VERSION ""

NS_ :

BS_:

BU_: MM5 STMM DD PDM BMS PM VCU

BO_ 3221225472 VECTOR__INDEPENDENT_SIG_MSG: 0 Vector__XXX
 SG_ VCU_counterMsg172 : 0|4@1+ (1,0) [0|15] "" Vector__XXX
 SG_ VCU_groundSpeed : 0|16@1- (0.1,0) [0|120] "mph" Vector__XXX
 SG_ VCU_groundSpeedLeft : 0|16@1- (0.1,0) [0|120] "mph" Vector__XXX
 SG_ VCU_groundSpeedRight : 0|16@1- (0.1,0) [0|120] "mph" Vector__XXX
 SG_ VCU_driveSpeed : 0|16@1- (0.1,0) [0|120] "mph" Vector__XXX
 SG_ VCU_driveSpeedLeft : 0|16@1- (0.1,0) [0|120] "mph" Vector__XXX
 SG_ VCU_driveSpeedRight : 0|16@1- (0.1,0) [0|120] "mph" Vector__XXX

BO_ 173 VCU_173: 8 Vector__XXX
 SG_ VCU_driveSpeed : 32|16@1- (0.1,0) [-3276.8|3276.7] "mph" Vector__XXX
 SG_ VCU_groundSpeed : 16|16@1- (0.1,0) [-3276.8|3276.7] "mph" Vector__XXX
 SG_ VCU_counterMsg173 : 0|4@1+ (1,0) [0|15] "" Vector__XXX

BO_ 172 VCU_172: 8 Vector__XXX
 SG_ VCU_brakePosR : 24|16@1- (0.1,0) [-3276.8|3276.7] "%" Vector__XXX
 SG_ VCU_brakePosF : 8|16@1- (0.1,0) [-3276.8|3276.7] "%" Vector__XXX
 SG_ VCU_counterMsg172 : 0|4@1+ (1,0) [0|15] "" Vector__XXX

BO_ 171 VCU_171: 8 Vector__XXX
 SG_ VCU_throttlePos2 : 32|16@1- (0.1,0) [0|0] "%" Vector__XXX
 SG_ VCU_throttlePos1 : 16|16@1- (0.1,0) [-3276.8|3276.7] "%" Vector__XXX
 SG_ VCU_counterMsg171 : 0|4@1+ (1,0) [0|15] "" Vector__XXX

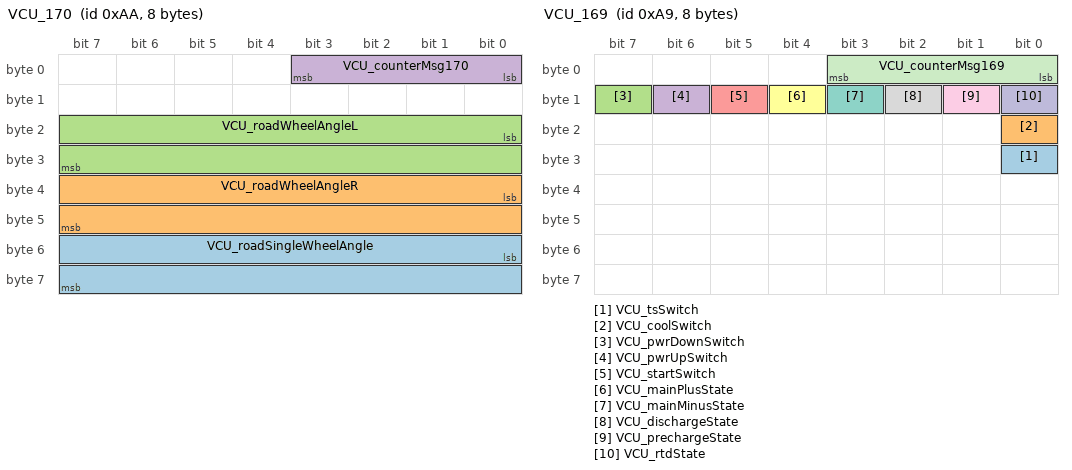
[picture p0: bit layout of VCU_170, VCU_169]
BO_ 170 VCU_170: 8 Vector__XXX
 SG_ VCU_roadSingleWheelAngle : 48|16@1- (0.1,0) [-3276.8|3276.7] "deg" Vector__XXX
 SG_ VCU_roadWheelAngleR : 32|16@1- (0.1,0) [-3276.8|3276.7] "deg" Vector__XXX
 SG_ VCU_roadWheelAngleL : 16|16@1- (0.1,0) [-3276.8|3276.7] "deg" Vector__XXX
 SG_ VCU_counterMsg170 : 0|4@1+ (1,0) [0|15] "" Vector__XXX

BO_ 169 VCU_169: 8 Vector__XXX
 SG_ VCU_tsSwitch : 24|1@1+ (1,0) [0|1] "" Vector__XXX
 SG_ VCU_coolSwitch : 16|1@1+ (1,0) [0|1] "" Vector__XXX
 SG_ VCU_pwrDownSwitch : 15|1@1+ (1,0) [0|1] "" Vector__XXX
 SG_ VCU_pwrUpSwitch : 14|1@1+ (1,0) [0|1] "" Vector__XXX
 SG_ VCU_startSwitch : 13|1@1+ (1,0) [0|1] "" Vector__XXX
 SG_ VCU_mainPlusState : 12|1@1+ (1,0) [0|1] "" Vector__XXX
 SG_ VCU_mainMinusState : 11|1@1+ (1,0) [0|1] "" Vector__XXX
 SG_ VCU_dischargeState : 10|1@1+ (1,0) [0|1] "" Vector__XXX
 SG_ VCU_prechargeState : 9|1@1+ (1,0) [0|1] "" Vector__XXX
 SG_ VCU_rtdState : 8|1@1+ (1,0) [0|1] "" Vector__XXX
 SG_ VCU_counterMsg169 : 0|4@1+ (1,0) [0|15] "" Vector__XXX

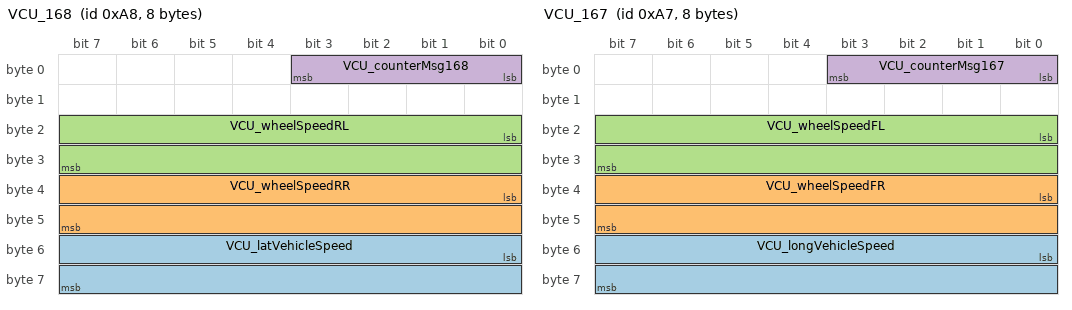
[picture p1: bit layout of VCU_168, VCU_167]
BO_ 168 VCU_168: 8 Vector__XXX
 SG_ VCU_latVehicleSpeed : 48|16@1- (0.1,0) [-3276.8|3276.7] "mph" Vector__XXX
 SG_ VCU_wheelSpeedRR : 32|16@1- (0.1,0) [-3276.8|3276.7] "mph" Vector__XXX
 SG_ VCU_wheelSpeedRL : 16|16@1- (0.1,0) [-3276.8|3276.7] "mph" Vector__XXX
 SG_ VCU_counterMsg168 : 0|4@1+ (1,0) [0|15] "" Vector__XXX

BO_ 167 VCU_167: 8 Vector__XXX
 SG_ VCU_longVehicleSpeed : 48|16@1- (0.1,0) [-3276.8|3276.7] "mph" Vector__XXX
 SG_ VCU_wheelSpeedFR : 32|16@1- (0.1,0) [-3276.8|3276.7] "mph" Vector__XXX
 SG_ VCU_wheelSpeedFL : 16|16@1- (0.1,0) [-3276.8|3276.7] "mph" Vector__XXX
 SG_ VCU_counterMsg167 : 0|4@1+ (1,0) [0|15] "" Vector__XXX

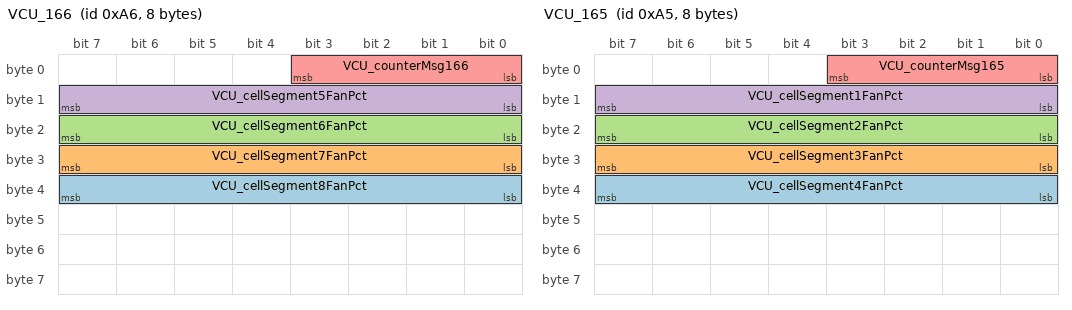
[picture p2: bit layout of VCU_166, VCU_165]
BO_ 166 VCU_166: 8 Vector__XXX
 SG_ VCU_cellSegment8FanPct : 32|8@1+ (1,0) [0|255] "%" Vector__XXX
 SG_ VCU_cellSegment7FanPct : 24|8@1+ (1,0) [0|255] "%" Vector__XXX
 SG_ VCU_cellSegment6FanPct : 16|8@1+ (1,0) [0|255] "%" Vector__XXX
 SG_ VCU_cellSegment5FanPct : 8|8@1+ (1,0) [0|255] "%" Vector__XXX
 SG_ VCU_counterMsg166 : 0|4@1+ (1,0) [0|15] "" Vector__XXX

BO_ 165 VCU_165: 8 Vector__XXX
 SG_ VCU_cellSegment4FanPct : 32|8@1+ (1,0) [0|255] "%" Vector__XXX
 SG_ VCU_cellSegment3FanPct : 24|8@1+ (1,0) [0|255] "%" Vector__XXX
 SG_ VCU_cellSegment2FanPct : 16|8@1+ (1,0) [0|255] "%" Vector__XXX
 SG_ VCU_cellSegment1FanPct : 8|8@1+ (1,0) [0|255] "%" Vector__XXX
 SG_ VCU_counterMsg165 : 0|4@1+ (1,0) [0|15] "" Vector__XXX

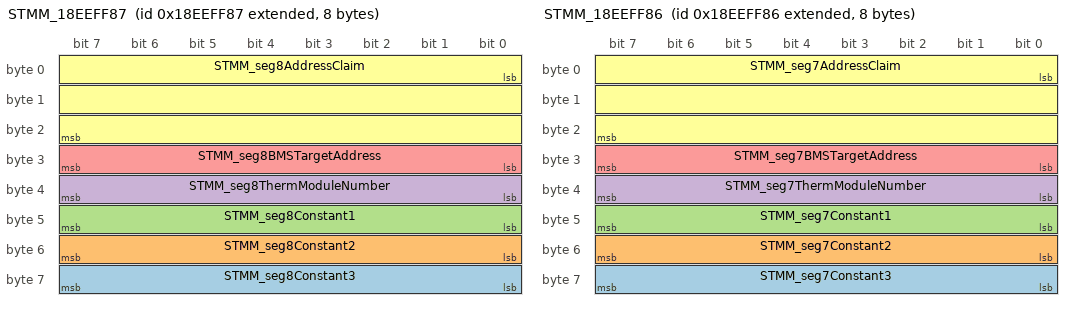
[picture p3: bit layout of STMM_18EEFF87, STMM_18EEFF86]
BO_ 2565799815 STMM_18EEFF87: 8 STMM
 SG_ STMM_seg8Constant3 : 56|8@1+ (1,0) [0|255] "" Vector__XXX
 SG_ STMM_seg8Constant2 : 48|8@1+ (1,0) [0|255] "" Vector__XXX
 SG_ STMM_seg8Constant1 : 40|8@1+ (1,0) [0|255] "" Vector__XXX
 SG_ STMM_seg8ThermModuleNumber : 32|8@1+ (1,0) [0|255] "" Vector__XXX
 SG_ STMM_seg8BMSTargetAddress : 24|8@1+ (1,0) [0|255] "" Vector__XXX
 SG_ STMM_seg8AddressClaim : 0|24@1+ (1,0) [0|16777215] "" Vector__XXX

BO_ 2565799814 STMM_18EEFF86: 8 STMM
 SG_ STMM_seg7Constant3 : 56|8@1+ (1,0) [0|255] "" Vector__XXX
 SG_ STMM_seg7Constant2 : 48|8@1+ (1,0) [0|255] "" Vector__XXX
 SG_ STMM_seg7Constant1 : 40|8@1+ (1,0) [0|255] "" Vector__XXX
 SG_ STMM_seg7ThermModuleNumber : 32|8@1+ (1,0) [0|255] "" Vector__XXX
 SG_ STMM_seg7BMSTargetAddress : 24|8@1+ (1,0) [0|255] "" Vector__XXX
 SG_ STMM_seg7AddressClaim : 0|24@1+ (1,0) [0|16777215] "" Vector__XXX

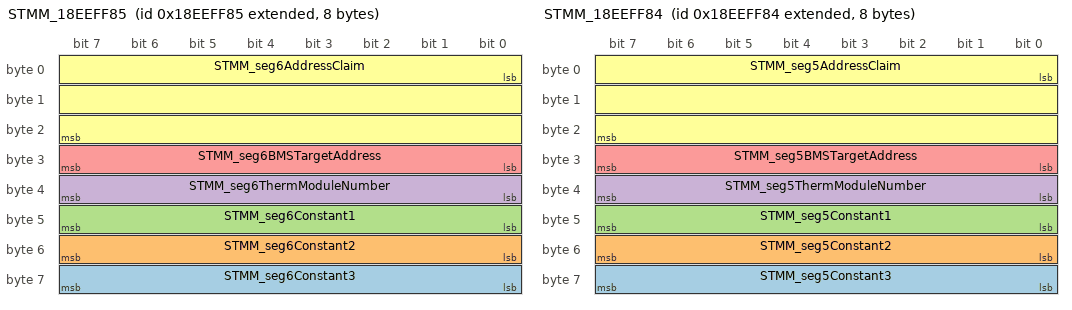
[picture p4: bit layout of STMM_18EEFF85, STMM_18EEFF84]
BO_ 2565799813 STMM_18EEFF85: 8 STMM
 SG_ STMM_seg6Constant3 : 56|8@1+ (1,0) [0|255] "" Vector__XXX
 SG_ STMM_seg6Constant2 : 48|8@1+ (1,0) [0|255] "" Vector__XXX
 SG_ STMM_seg6Constant1 : 40|8@1+ (1,0) [0|255] "" Vector__XXX
 SG_ STMM_seg6ThermModuleNumber : 32|8@1+ (1,0) [0|255] "" Vector__XXX
 SG_ STMM_seg6BMSTargetAddress : 24|8@1+ (1,0) [0|255] "" Vector__XXX
 SG_ STMM_seg6AddressClaim : 0|24@1+ (1,0) [0|16777215] "" Vector__XXX

BO_ 2565799812 STMM_18EEFF84: 8 STMM
 SG_ STMM_seg5Constant3 : 56|8@1+ (1,0) [0|255] "" Vector__XXX
 SG_ STMM_seg5Constant2 : 48|8@1+ (1,0) [0|255] "" Vector__XXX
 SG_ STMM_seg5Constant1 : 40|8@1+ (1,0) [0|255] "" Vector__XXX
 SG_ STMM_seg5ThermModuleNumber : 32|8@1+ (1,0) [0|255] "" Vector__XXX
 SG_ STMM_seg5BMSTargetAddress : 24|8@1+ (1,0) [0|255] "" Vector__XXX
 SG_ STMM_seg5AddressClaim : 0|24@1+ (1,0) [0|16777215] "" Vector__XXX

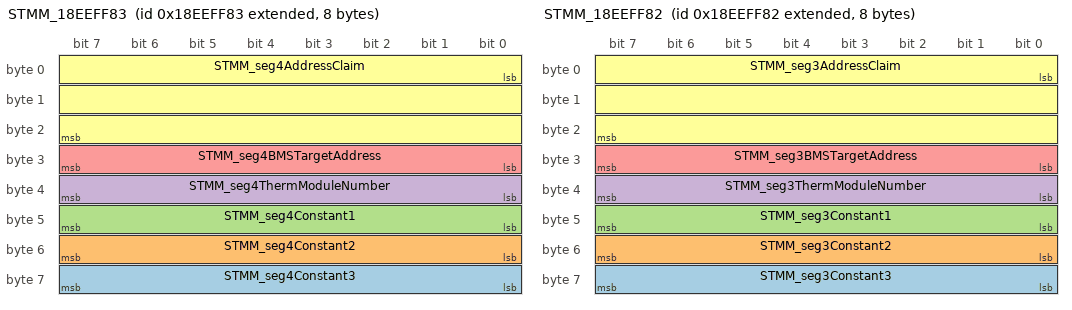
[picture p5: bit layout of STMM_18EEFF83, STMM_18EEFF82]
BO_ 2565799811 STMM_18EEFF83: 8 STMM
 SG_ STMM_seg4Constant3 : 56|8@1+ (1,0) [0|255] "" Vector__XXX
 SG_ STMM_seg4Constant2 : 48|8@1+ (1,0) [0|255] "" Vector__XXX
 SG_ STMM_seg4Constant1 : 40|8@1+ (1,0) [0|255] "" Vector__XXX
 SG_ STMM_seg4ThermModuleNumber : 32|8@1+ (1,0) [0|255] "" Vector__XXX
 SG_ STMM_seg4BMSTargetAddress : 24|8@1+ (1,0) [0|255] "" Vector__XXX
 SG_ STMM_seg4AddressClaim : 0|24@1+ (1,0) [0|16777215] "" Vector__XXX

BO_ 2565799810 STMM_18EEFF82: 8 STMM
 SG_ STMM_seg3Constant3 : 56|8@1+ (1,0) [0|255] "" Vector__XXX
 SG_ STMM_seg3Constant2 : 48|8@1+ (1,0) [0|255] "" Vector__XXX
 SG_ STMM_seg3Constant1 : 40|8@1+ (1,0) [0|255] "" Vector__XXX
 SG_ STMM_seg3ThermModuleNumber : 32|8@1+ (1,0) [0|255] "" Vector__XXX
 SG_ STMM_seg3BMSTargetAddress : 24|8@1+ (1,0) [0|255] "" Vector__XXX
 SG_ STMM_seg3AddressClaim : 0|24@1+ (1,0) [0|16777215] "" Vector__XXX

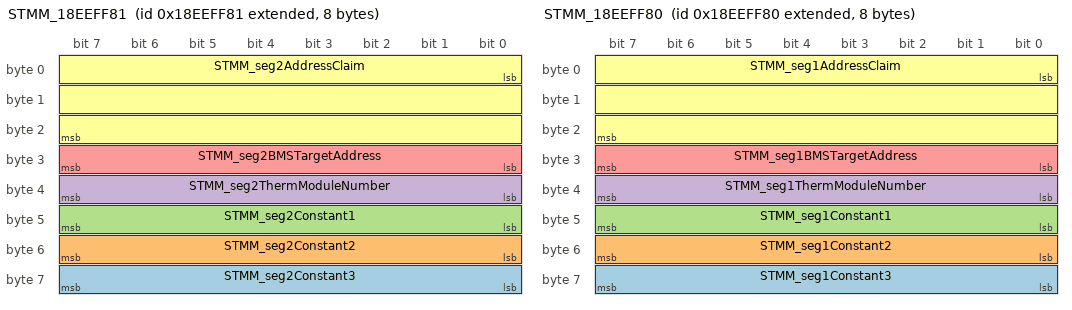
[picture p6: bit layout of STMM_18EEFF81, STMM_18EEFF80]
BO_ 2565799809 STMM_18EEFF81: 8 STMM
 SG_ STMM_seg2Constant3 : 56|8@1+ (1,0) [0|255] "" Vector__XXX
 SG_ STMM_seg2Constant2 : 48|8@1+ (1,0) [0|255] "" Vector__XXX
 SG_ STMM_seg2Constant1 : 40|8@1+ (1,0) [0|255] "" Vector__XXX
 SG_ STMM_seg2ThermModuleNumber : 32|8@1+ (1,0) [0|255] "" Vector__XXX
 SG_ STMM_seg2BMSTargetAddress : 24|8@1+ (1,0) [0|255] "" Vector__XXX
 SG_ STMM_seg2AddressClaim : 0|24@1+ (1,0) [0|16777215] "" Vector__XXX

BO_ 2565799808 STMM_18EEFF80: 8 STMM
 SG_ STMM_seg1Constant3 : 56|8@1+ (1,0) [0|255] "" Vector__XXX
 SG_ STMM_seg1Constant2 : 48|8@1+ (1,0) [0|255] "" Vector__XXX
 SG_ STMM_seg1Constant1 : 40|8@1+ (1,0) [0|255] "" Vector__XXX
 SG_ STMM_seg1ThermModuleNumber : 32|8@1+ (1,0) [0|255] "" Vector__XXX
 SG_ STMM_seg1BMSTargetAddress : 24|8@1+ (1,0) [0|255] "" Vector__XXX
 SG_ STMM_seg1AddressClaim : 0|24@1+ (1,0) [0|16777215] "" Vector__XXX

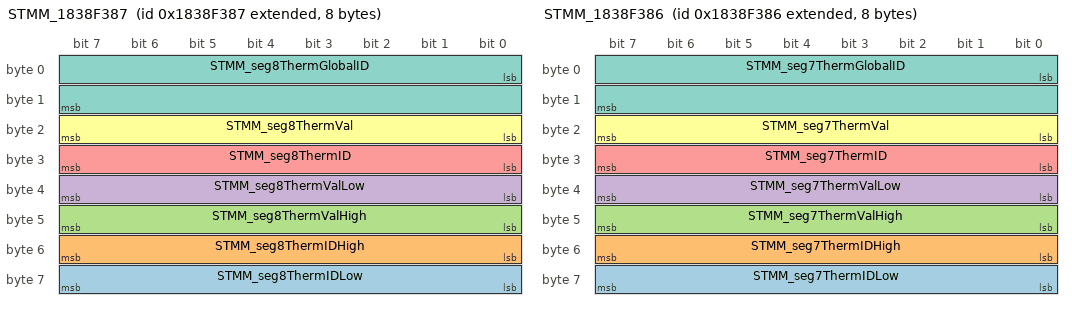
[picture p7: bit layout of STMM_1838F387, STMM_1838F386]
BO_ 2553869191 STMM_1838F387: 8 STMM
 SG_ STMM_seg8ThermIDLow : 56|8@1+ (1,0) [0|255] "" Vector__XXX
 SG_ STMM_seg8ThermIDHigh : 48|8@1+ (1,0) [0|255] "" Vector__XXX
 SG_ STMM_seg8ThermValHigh : 40|8@1- (1,0) [-128|127] "degC" Vector__XXX
 SG_ STMM_seg8ThermValLow : 32|8@1- (1,0) [-128|127] "degC" Vector__XXX
 SG_ STMM_seg8ThermID : 24|8@1+ (1,0) [0|255] "" Vector__XXX
 SG_ STMM_seg8ThermVal : 16|8@1- (1,0) [-128|127] "degC" Vector__XXX
 SG_ STMM_seg8ThermGlobalID : 0|16@1+ (1,0) [0|65535] "" Vector__XXX

BO_ 2553869190 STMM_1838F386: 8 STMM
 SG_ STMM_seg7ThermIDLow : 56|8@1+ (1,0) [0|255] "" Vector__XXX
 SG_ STMM_seg7ThermIDHigh : 48|8@1+ (1,0) [0|255] "" Vector__XXX
 SG_ STMM_seg7ThermValHigh : 40|8@1- (1,0) [-128|127] "degC" Vector__XXX
 SG_ STMM_seg7ThermValLow : 32|8@1- (1,0) [-128|127] "degC" Vector__XXX
 SG_ STMM_seg7ThermID : 24|8@1+ (1,0) [0|255] "" Vector__XXX
 SG_ STMM_seg7ThermVal : 16|8@1- (1,0) [-128|127] "degC" Vector__XXX
 SG_ STMM_seg7ThermGlobalID : 0|16@1+ (1,0) [0|65535] "" Vector__XXX

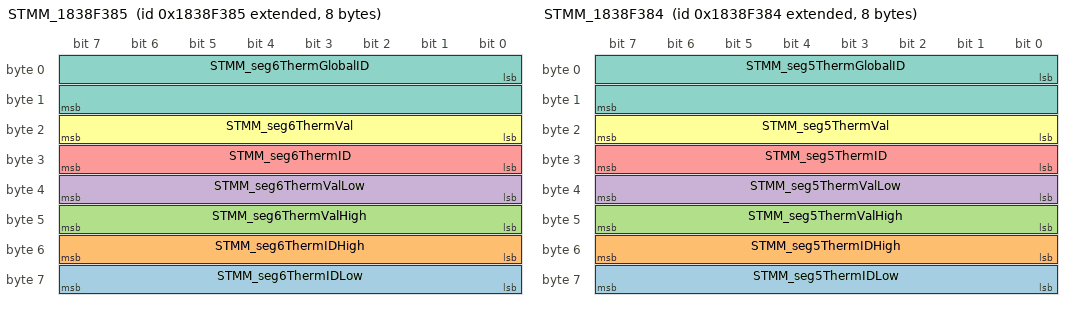
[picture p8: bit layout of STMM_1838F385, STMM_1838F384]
BO_ 2553869189 STMM_1838F385: 8 STMM
 SG_ STMM_seg6ThermIDLow : 56|8@1+ (1,0) [0|255] "" Vector__XXX
 SG_ STMM_seg6ThermIDHigh : 48|8@1+ (1,0) [0|255] "" Vector__XXX
 SG_ STMM_seg6ThermValHigh : 40|8@1- (1,0) [-128|127] "degC" Vector__XXX
 SG_ STMM_seg6ThermValLow : 32|8@1- (1,0) [-128|127] "degC" Vector__XXX
 SG_ STMM_seg6ThermID : 24|8@1+ (1,0) [0|255] "" Vector__XXX
 SG_ STMM_seg6ThermVal : 16|8@1- (1,0) [-128|127] "degC" Vector__XXX
 SG_ STMM_seg6ThermGlobalID : 0|16@1+ (1,0) [0|65535] "" Vector__XXX

BO_ 2553869188 STMM_1838F384: 8 STMM
 SG_ STMM_seg5ThermIDLow : 56|8@1+ (1,0) [0|255] "" Vector__XXX
 SG_ STMM_seg5ThermIDHigh : 48|8@1+ (1,0) [0|255] "" Vector__XXX
 SG_ STMM_seg5ThermValHigh : 40|8@1- (1,0) [-128|127] "degC" Vector__XXX
 SG_ STMM_seg5ThermValLow : 32|8@1- (1,0) [-128|127] "degC" Vector__XXX
 SG_ STMM_seg5ThermID : 24|8@1+ (1,0) [0|255] "" Vector__XXX
 SG_ STMM_seg5ThermVal : 16|8@1- (1,0) [-128|127] "degC" Vector__XXX
 SG_ STMM_seg5ThermGlobalID : 0|16@1+ (1,0) [0|65535] "" Vector__XXX

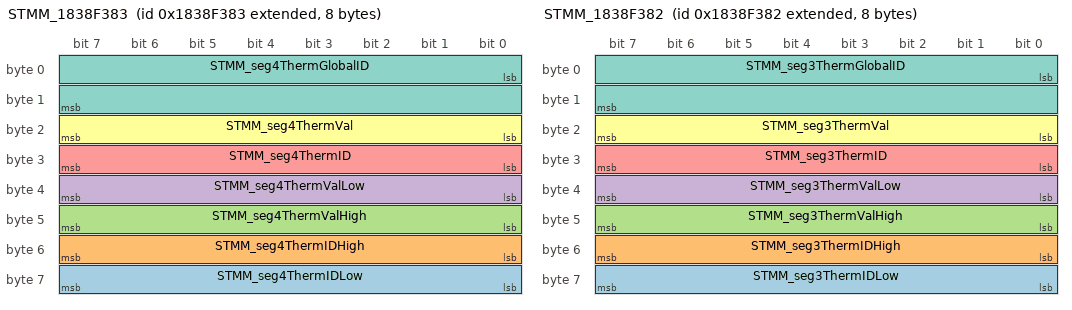
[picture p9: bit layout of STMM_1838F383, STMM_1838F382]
BO_ 2553869187 STMM_1838F383: 8 STMM
 SG_ STMM_seg4ThermIDLow : 56|8@1+ (1,0) [0|255] "" Vector__XXX
 SG_ STMM_seg4ThermIDHigh : 48|8@1+ (1,0) [0|255] "" Vector__XXX
 SG_ STMM_seg4ThermValHigh : 40|8@1- (1,0) [-128|127] "degC" Vector__XXX
 SG_ STMM_seg4ThermValLow : 32|8@1- (1,0) [-128|127] "degC" Vector__XXX
 SG_ STMM_seg4ThermID : 24|8@1+ (1,0) [0|255] "" Vector__XXX
 SG_ STMM_seg4ThermVal : 16|8@1- (1,0) [-128|127] "degC" Vector__XXX
 SG_ STMM_seg4ThermGlobalID : 0|16@1+ (1,0) [0|65535] "" Vector__XXX

BO_ 2553869186 STMM_1838F382: 8 STMM
 SG_ STMM_seg3ThermIDLow : 56|8@1+ (1,0) [0|255] "" Vector__XXX
 SG_ STMM_seg3ThermIDHigh : 48|8@1+ (1,0) [0|255] "" Vector__XXX
 SG_ STMM_seg3ThermValHigh : 40|8@1- (1,0) [-128|127] "degC" Vector__XXX
 SG_ STMM_seg3ThermValLow : 32|8@1- (1,0) [-128|127] "degC" Vector__XXX
 SG_ STMM_seg3ThermID : 24|8@1+ (1,0) [0|255] "" Vector__XXX
 SG_ STMM_seg3ThermVal : 16|8@1- (1,0) [-128|127] "degC" Vector__XXX
 SG_ STMM_seg3ThermGlobalID : 0|16@1+ (1,0) [0|65535] "" Vector__XXX

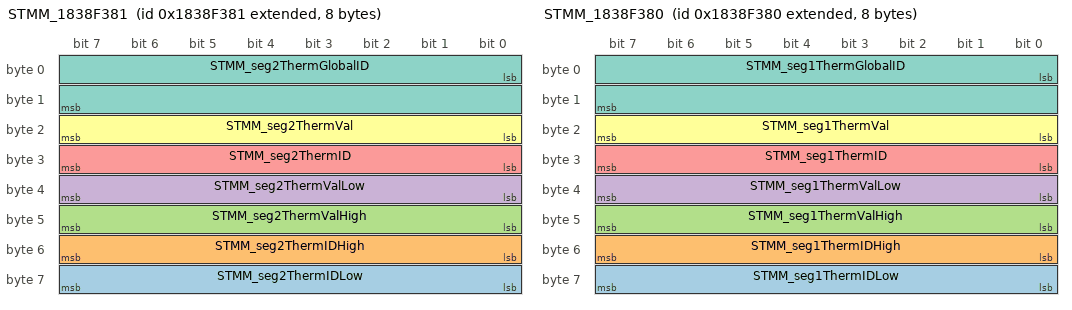
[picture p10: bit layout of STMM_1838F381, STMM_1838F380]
BO_ 2553869185 STMM_1838F381: 8 STMM
 SG_ STMM_seg2ThermIDLow : 56|8@1+ (1,0) [0|255] "" Vector__XXX
 SG_ STMM_seg2ThermIDHigh : 48|8@1+ (1,0) [0|255] "" Vector__XXX
 SG_ STMM_seg2ThermValHigh : 40|8@1- (1,0) [-128|127] "degC" Vector__XXX
 SG_ STMM_seg2ThermValLow : 32|8@1- (1,0) [-128|127] "degC" Vector__XXX
 SG_ STMM_seg2ThermID : 24|8@1+ (1,0) [0|255] "" Vector__XXX
 SG_ STMM_seg2ThermVal : 16|8@1- (1,0) [-128|127] "degC" Vector__XXX
 SG_ STMM_seg2ThermGlobalID : 0|16@1+ (1,0) [0|65535] "" Vector__XXX

BO_ 2553869184 STMM_1838F380: 8 STMM
 SG_ STMM_seg1ThermIDLow : 56|8@1+ (1,0) [0|255] "" Vector__XXX
 SG_ STMM_seg1ThermIDHigh : 48|8@1+ (1,0) [0|255] "" Vector__XXX
 SG_ STMM_seg1ThermValHigh : 40|8@1- (1,0) [-128|127] "degC" Vector__XXX
 SG_ STMM_seg1ThermValLow : 32|8@1- (1,0) [-128|127] "degC" Vector__XXX
 SG_ STMM_seg1ThermID : 24|8@1+ (1,0) [0|255] "" Vector__XXX
 SG_ STMM_seg1ThermVal : 16|8@1- (1,0) [-128|127] "degC" Vector__XXX
 SG_ STMM_seg1ThermGlobalID : 0|16@1+ (1,0) [0|65535] "" Vector__XXX

BO_ 380 MM5_380: 8 MM5
 SG_ MM5_az : 32|16@1+ (-0.0001274,4.1745795) [-4.1745795|4.1745795] "g" Vector__XXX

BO_ 376 MM5_376: 8 MM5
 SG_ MM5_rollRate : 0|16@1+ (-0.005,163.9) [-163.775|163.9] "deg/s" Vector__XXX
 SG_ MM5_ax : 32|16@1+ (-0.0001274,4.1745795) [-4.1745795|4.1745795] "g" Vector__XXX

BO_ 372 MM5_372: 8 MM5
 SG_ MM5_yawRate : 0|16@1+ (0.005,-163.9) [-163.9|163.775] "deg/s" Vector__XXX
 SG_ MM5_ay : 32|16@1+ (-0.0001274,4.1745795) [-4.1745795|4.1745795] "g" Vector__XXX

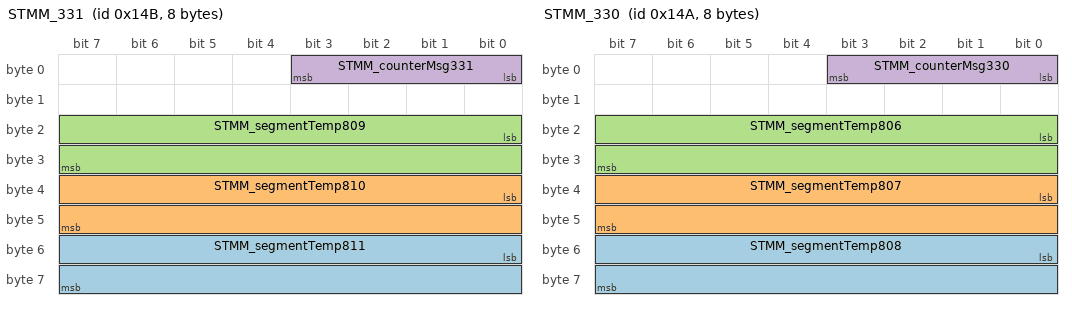
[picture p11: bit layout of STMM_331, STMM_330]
BO_ 331 STMM_331: 8 STMM
 SG_ STMM_segmentTemp811 : 48|16@1- (0.1,0) [-5|120] "degC" Vector__XXX
 SG_ STMM_segmentTemp810 : 32|16@1- (0.1,0) [-5|120] "degC" Vector__XXX
 SG_ STMM_segmentTemp809 : 16|16@1- (0.1,0) [-5|120] "degC" Vector__XXX
 SG_ STMM_counterMsg331 : 0|4@1+ (1,0) [0|15] "" Vector__XXX

BO_ 330 STMM_330: 8 STMM
 SG_ STMM_segmentTemp808 : 48|16@1- (0.1,0) [-5|120] "degC" Vector__XXX
 SG_ STMM_segmentTemp807 : 32|16@1- (0.1,0) [-5|120] "degC" Vector__XXX
 SG_ STMM_segmentTemp806 : 16|16@1- (0.1,0) [-5|120] "degC" Vector__XXX
 SG_ STMM_counterMsg330 : 0|4@1+ (1,0) [0|15] "" Vector__XXX

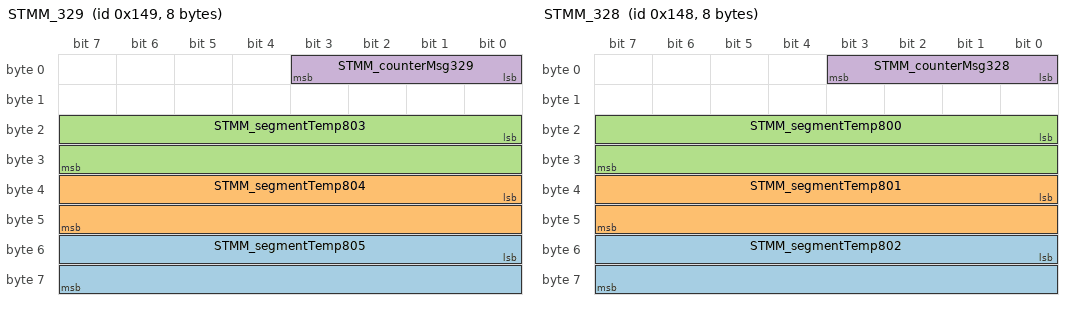
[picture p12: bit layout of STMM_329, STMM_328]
BO_ 329 STMM_329: 8 STMM
 SG_ STMM_segmentTemp805 : 48|16@1- (0.1,0) [-5|120] "degC" Vector__XXX
 SG_ STMM_segmentTemp804 : 32|16@1- (0.1,0) [-5|120] "degC" Vector__XXX
 SG_ STMM_segmentTemp803 : 16|16@1- (0.1,0) [-5|120] "degC" Vector__XXX
 SG_ STMM_counterMsg329 : 0|4@1+ (1,0) [0|15] "" Vector__XXX

BO_ 328 STMM_328: 8 STMM
 SG_ STMM_segmentTemp802 : 48|16@1- (0.1,0) [-5|120] "degC" Vector__XXX
 SG_ STMM_segmentTemp801 : 32|16@1- (0.1,0) [-5|120] "degC" Vector__XXX
 SG_ STMM_segmentTemp800 : 16|16@1- (0.1,0) [-5|120] "degC" Vector__XXX
 SG_ STMM_counterMsg328 : 0|4@1+ (1,0) [0|15] "" Vector__XXX

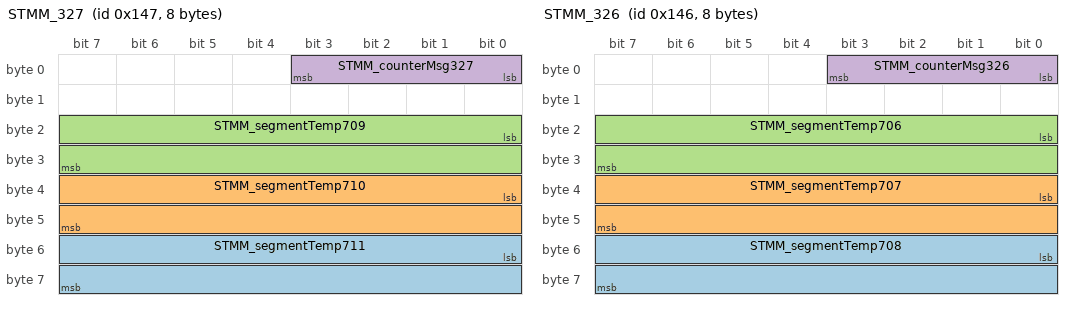
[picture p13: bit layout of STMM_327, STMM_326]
BO_ 327 STMM_327: 8 STMM
 SG_ STMM_segmentTemp711 : 48|16@1- (0.1,0) [-5|120] "degC" Vector__XXX
 SG_ STMM_segmentTemp710 : 32|16@1- (0.1,0) [-5|120] "degC" Vector__XXX
 SG_ STMM_segmentTemp709 : 16|16@1- (0.1,0) [-5|120] "degC" Vector__XXX
 SG_ STMM_counterMsg327 : 0|4@1+ (1,0) [0|15] "" Vector__XXX

BO_ 326 STMM_326: 8 STMM
 SG_ STMM_segmentTemp708 : 48|16@1- (0.1,0) [-5|120] "degC" Vector__XXX
 SG_ STMM_segmentTemp707 : 32|16@1- (0.1,0) [-5|120] "degC" Vector__XXX
 SG_ STMM_segmentTemp706 : 16|16@1- (0.1,0) [-5|120] "degC" Vector__XXX
 SG_ STMM_counterMsg326 : 0|4@1+ (1,0) [0|15] "" Vector__XXX

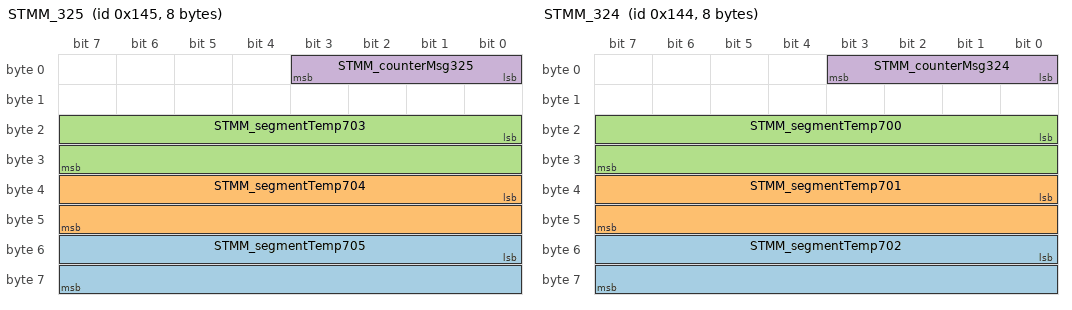
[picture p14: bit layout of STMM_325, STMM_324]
BO_ 325 STMM_325: 8 STMM
 SG_ STMM_segmentTemp705 : 48|16@1- (0.1,0) [-5|120] "degC" Vector__XXX
 SG_ STMM_segmentTemp704 : 32|16@1- (0.1,0) [-5|120] "degC" Vector__XXX
 SG_ STMM_segmentTemp703 : 16|16@1- (0.1,0) [-5|120] "degC" Vector__XXX
 SG_ STMM_counterMsg325 : 0|4@1+ (1,0) [0|15] "" Vector__XXX

BO_ 324 STMM_324: 8 STMM
 SG_ STMM_segmentTemp702 : 48|16@1- (0.1,0) [-5|120] "degC" Vector__XXX
 SG_ STMM_segmentTemp701 : 32|16@1- (0.1,0) [-5|120] "degC" Vector__XXX
 SG_ STMM_segmentTemp700 : 16|16@1- (0.1,0) [-5|120] "degC" Vector__XXX
 SG_ STMM_counterMsg324 : 0|4@1+ (1,0) [0|15] "" Vector__XXX

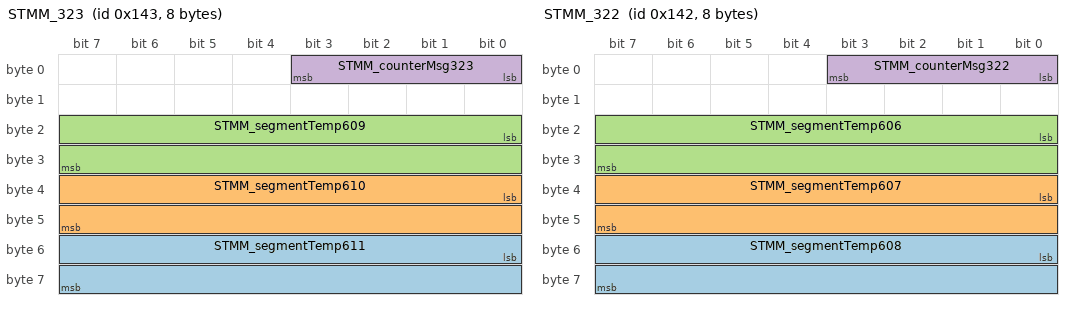
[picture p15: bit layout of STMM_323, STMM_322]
BO_ 323 STMM_323: 8 STMM
 SG_ STMM_segmentTemp611 : 48|16@1- (0.1,0) [-5|120] "degC" Vector__XXX
 SG_ STMM_segmentTemp610 : 32|16@1- (0.1,0) [-5|120] "degC" Vector__XXX
 SG_ STMM_segmentTemp609 : 16|16@1- (0.1,0) [-5|120] "degC" Vector__XXX
 SG_ STMM_counterMsg323 : 0|4@1+ (1,0) [0|15] "" Vector__XXX

BO_ 322 STMM_322: 8 STMM
 SG_ STMM_segmentTemp608 : 48|16@1- (0.1,0) [-5|120] "degC" Vector__XXX
 SG_ STMM_segmentTemp607 : 32|16@1- (0.1,0) [-5|120] "degC" Vector__XXX
 SG_ STMM_segmentTemp606 : 16|16@1- (0.1,0) [-5|120] "degC" Vector__XXX
 SG_ STMM_counterMsg322 : 0|4@1+ (1,0) [0|15] "" Vector__XXX

BO_ 321 STMM_321: 8 STMM
 SG_ STMM_segmentTemp605 : 48|16@1- (0.1,0) [-5|120] "degC" Vector__XXX
 SG_ STMM_segmentTemp604 : 32|16@1- (0.1,0) [-5|120] "degC" Vector__XXX
 SG_ STMM_segmentTemp603 : 16|16@1- (0.1,0) [-5|120] "degC" Vector__XXX
 SG_ STMM_counterMsg321 : 0|4@1+ (1,0) [0|15] "" Vector__XXX

BO_ 320 STMM_320: 8 STMM
 SG_ STMM_segmentTemp602 : 48|16@1- (0.1,0) [-5|120] "degC" Vector__XXX
 SG_ STMM_segmentTemp601 : 32|16@1- (0.1,0) [-5|120] "degC" Vector__XXX
 SG_ STMM_segmentTemp600 : 16|16@1- (0.1,0) [-5|120] "degC" Vector__XXX
 SG_ STMM_counterMsg320 : 0|4@1+ (1,0) [0|15] "" Vector__XXX

BO_ 319 STMM_319: 8 STMM
 SG_ STMM_segmentTemp511 : 48|16@1- (0.1,0) [-5|120] "degC" Vector__XXX
 SG_ STMM_segmentTemp510 : 32|16@1- (0.1,0) [-5|120] "degC" Vector__XXX
 SG_ STMM_segmentTemp509 : 16|16@1- (0.1,0) [-5|120] "degC" Vector__XXX
 SG_ STMM_counterMsg319 : 0|4@1+ (1,0) [0|15] "" Vector__XXX

BO_ 318 STMM_318: 8 STMM
 SG_ STMM_segmentTemp508 : 48|16@1- (0.1,0) [-5|120] "degC" Vector__XXX
 SG_ STMM_segmentTemp507 : 32|16@1- (0.1,0) [-5|120] "degC" Vector__XXX
 SG_ STMM_segmentTemp506 : 16|16@1- (0.1,0) [-5|120] "degC" Vector__XXX
 SG_ STMM_counterMsg318 : 0|4@1+ (1,0) [0|15] "" Vector__XXX

BO_ 317 STMM_317: 8 STMM
 SG_ STMM_segmentTemp505 : 48|16@1- (0.1,0) [-5|120] "degC" Vector__XXX
 SG_ STMM_segmentTemp504 : 32|16@1- (0.1,0) [-5|120] "degC" Vector__XXX
 SG_ STMM_segmentTemp503 : 16|16@1- (0.1,0) [-5|120] "degC" Vector__XXX
 SG_ STMM_counterMsg317 : 0|4@1+ (1,0) [0|15] "" Vector__XXX

BO_ 316 STMM_316: 8 STMM
 SG_ STMM_segmentTemp502 : 48|16@1- (0.1,0) [-5|120] "degC" Vector__XXX
 SG_ STMM_segmentTemp501 : 32|16@1- (0.1,0) [-5|120] "degC" Vector__XXX
 SG_ STMM_segmentTemp500 : 16|16@1- (0.1,0) [-5|120] "degC" Vector__XXX
 SG_ STMM_counterMsg316 : 0|4@1+ (1,0) [0|15] "" Vector__XXX

BO_ 315 STMM_315: 8 STMM
 SG_ STMM_segmentTemp411 : 48|16@1- (0.1,0) [-5|120] "degC" Vector__XXX
 SG_ STMM_segmentTemp410 : 32|16@1- (0.1,0) [-5|120] "degC" Vector__XXX
 SG_ STMM_segmentTemp409 : 16|16@1- (0.1,0) [-5|120] "degC" Vector__XXX
 SG_ STMM_counterMsg315 : 0|4@1+ (1,0) [0|15] "" Vector__XXX

BO_ 314 STMM_314: 8 STMM
 SG_ STMM_segmentTemp408 : 48|16@1- (0.1,0) [-5|120] "degC" Vector__XXX
 SG_ STMM_segmentTemp407 : 32|16@1- (0.1,0) [-5|120] "degC" Vector__XXX
 SG_ STMM_segmentTemp406 : 16|16@1- (0.1,0) [-5|120] "degC" Vector__XXX
 SG_ STMM_counterMsg314 : 0|4@1+ (1,0) [0|15] "" Vector__XXX

BO_ 313 STMM_313: 8 STMM
 SG_ STMM_segmentTemp405 : 48|16@1- (0.1,0) [-5|120] "degC" Vector__XXX
 SG_ STMM_segmentTemp404 : 32|16@1- (0.1,0) [-5|120] "degC" Vector__XXX
 SG_ STMM_segmentTemp403 : 16|16@1- (0.1,0) [-5|120] "degC" Vector__XXX
 SG_ STMM_counterMsg313 : 0|4@1+ (1,0) [0|15] "" Vector__XXX

BO_ 312 STMM_312: 8 STMM
 SG_ STMM_segmentTemp402 : 48|16@1- (0.1,0) [-5|120] "degC" Vector__XXX
 SG_ STMM_segmentTemp401 : 32|16@1- (0.1,0) [-5|120] "degC" Vector__XXX
 SG_ STMM_segmentTemp400 : 16|16@1- (0.1,0) [-5|120] "degC" Vector__XXX
 SG_ STMM_counterMsg312 : 0|4@1+ (1,0) [0|15] "" Vector__XXX

BO_ 311 STMM_311: 8 STMM
 SG_ STMM_segmentTemp311 : 48|16@1- (0.1,0) [-5|120] "degC" Vector__XXX
 SG_ STMM_segmentTemp310 : 32|16@1- (0.1,0) [-5|120] "degC" Vector__XXX
 SG_ STMM_segmentTemp309 : 16|16@1- (0.1,0) [-5|120] "degC" Vector__XXX
 SG_ STMM_counterMsg311 : 0|4@1+ (1,0) [0|15] "" Vector__XXX

BO_ 310 STMM_310: 8 STMM
 SG_ STMM_segmentTemp308 : 48|16@1- (0.1,0) [-5|120] "degC" Vector__XXX
 SG_ STMM_segmentTemp307 : 32|16@1- (0.1,0) [-5|120] "degC" Vector__XXX
 SG_ STMM_segmentTemp306 : 16|16@1- (0.1,0) [-5|120] "degC" Vector__XXX
 SG_ STMM_counterMsg310 : 0|4@1+ (1,0) [0|15] "" Vector__XXX

BO_ 309 STMM_309: 8 STMM
 SG_ STMM_segmentTemp305 : 48|16@1- (0.1,0) [-5|120] "degC" Vector__XXX
 SG_ STMM_segmentTemp304 : 32|16@1- (0.1,0) [-5|120] "degC" Vector__XXX
 SG_ STMM_segmentTemp303 : 16|16@1- (0.1,0) [-5|120] "degC" Vector__XXX
 SG_ STMM_counterMsg309 : 0|4@1+ (1,0) [0|15] "" Vector__XXX

BO_ 308 STMM_308: 8 STMM
 SG_ STMM_segmentTemp302 : 48|16@1- (0.1,0) [-5|120] "degC" Vector__XXX
 SG_ STMM_segmentTemp301 : 32|16@1- (0.1,0) [-5|120] "degC" Vector__XXX
 SG_ STMM_segmentTemp300 : 16|16@1- (0.1,0) [-5|120] "degC" Vector__XXX
 SG_ STMM_counterMsg308 : 0|4@1+ (1,0) [0|15] "" Vector__XXX

BO_ 307 STMM_307: 8 STMM
 SG_ STMM_segmentTemp211 : 48|16@1- (0.1,0) [-5|120] "degC" Vector__XXX
 SG_ STMM_segmentTemp210 : 32|16@1- (0.1,0) [-5|120] "degC" Vector__XXX
 SG_ STMM_segmentTemp209 : 16|16@1- (0.1,0) [-5|120] "degC" Vector__XXX
 SG_ STMM_counterMsg307 : 0|4@1+ (1,0) [0|15] "" Vector__XXX

BO_ 306 STMM_306: 8 STMM
 SG_ STMM_segmentTemp208 : 48|16@1- (0.1,0) [-5|120] "degC" Vector__XXX
 SG_ STMM_segmentTemp207 : 32|16@1- (0.1,0) [-5|120] "degC" Vector__XXX
 SG_ STMM_segmentTemp206 : 16|16@1- (0.1,0) [-5|120] "degC" Vector__XXX
 SG_ STMM_counterMsg306 : 0|4@1+ (1,0) [0|15] "" Vector__XXX

BO_ 305 STMM_305: 8 STMM
 SG_ STMM_segmentTemp205 : 48|16@1- (0.1,0) [-5|120] "degC" Vector__XXX
 SG_ STMM_segmentTemp204 : 32|16@1- (0.1,0) [-5|120] "degC" Vector__XXX
 SG_ STMM_segmentTemp203 : 16|16@1- (0.1,0) [-5|120] "degC" Vector__XXX
 SG_ STMM_counterMsg305 : 0|4@1+ (1,0) [0|15] "" Vector__XXX

BO_ 304 STMM_304: 8 STMM
 SG_ STMM_segmentTemp202 : 48|16@1- (0.1,0) [-5|120] "degC" Vector__XXX
 SG_ STMM_segmentTemp201 : 32|16@1- (0.1,0) [-5|120] "degC" Vector__XXX
 SG_ STMM_segmentTemp200 : 16|16@1- (0.1,0) [-5|120] "degC" Vector__XXX
 SG_ STMM_counterMsg304 : 0|4@1+ (1,0) [0|15] "" Vector__XXX

BO_ 303 STMM_303: 8 STMM
 SG_ STMM_segmentTemp111 : 48|16@1- (0.1,0) [-5|120] "degC" Vector__XXX
 SG_ STMM_segmentTemp110 : 32|16@1- (0.1,0) [-5|120] "degC" Vector__XXX
 SG_ STMM_segmentTemp109 : 16|16@1- (0.1,0) [-5|120] "degC" Vector__XXX
 SG_ STMM_counterMsg303 : 0|4@1+ (1,0) [0|15] "" Vector__XXX

BO_ 302 STMM_302: 8 STMM
 SG_ STMM_segmentTemp108 : 48|16@1- (0.1,0) [-5|120] "degC" Vector__XXX
 SG_ STMM_segmentTemp107 : 32|16@1- (0.1,0) [-5|120] "degC" Vector__XXX
 SG_ STMM_segmentTemp106 : 16|16@1- (0.1,0) [-5|120] "degC" Vector__XXX
 SG_ STMM_counterMsg302 : 0|4@1+ (1,0) [0|15] "" Vector__XXX

BO_ 301 STMM_301: 8 STMM
 SG_ STMM_segmentTemp105 : 48|16@1- (0.1,0) [-5|120] "degC" Vector__XXX
 SG_ STMM_segmentTemp104 : 32|16@1- (0.1,0) [-5|120] "degC" Vector__XXX
 SG_ STMM_segmentTemp103 : 16|16@1- (0.1,0) [-5|120] "degC" Vector__XXX
 SG_ STMM_counterMsg301 : 0|4@1+ (1,0) [0|15] "" Vector__XXX

BO_ 300 STMM_300: 8 STMM
 SG_ STMM_segmentTemp102 : 48|16@1- (0.1,0) [-5|120] "degC" Vector__XXX
 SG_ STMM_segmentTemp101 : 32|16@1- (0.1,0) [-5|120] "degC" Vector__XXX
 SG_ STMM_segmentTemp100 : 16|16@1- (0.1,0) [-5|120] "degC" Vector__XXX
 SG_ STMM_counterMsg300 : 0|4@1+ (1,0) [0|15] "" Vector__XXX

BO_ 250 DD_250: 8 DD
 SG_ DD_teensyTemp : 32|16@1- (0.1,0) [0|150] "degC" Vector__XXX
 SG_ DD_counterMsg250 : 0|4@1+ (1,0) [0|15] "" Vector__XXX
 SG_ DD_boardTemp : 16|16@1- (0.1,0) [0|150] "degC" Vector__XXX

BO_ 414 PDM_414: 8 PDM
 SG_ PDM_runtimeMinutes : 48|16@1- (1,0) [-32768|32767] "mins" Vector__XXX
 SG_ PDM_runtimeHours : 32|16@1- (1,0) [-32768|32767] "hrs" Vector__XXX
 SG_ PDM_counterMsg414 : 0|4@1+ (1,0) [0|15] "" Vector__XXX
 SG_ PDM_carMiles : 16|16@1- (0.1,0) [-3276.8|3276.7] "mi" Vector__XXX

BO_ 413 PDM_413: 8 PDM
 SG_ PDM_keepAliveVoltMin : 48|16@1- (0.001,0) [-32.768|32.767] "V" Vector__XXX
 SG_ PDM_keepAliveVoltMax : 32|16@1- (0.001,0) [-32.768|32.767] "V" Vector__XXX
 SG_ PDM_keepAliveVoltAvg : 16|16@1- (0.001,0) [-32.768|32.767] "V" Vector__XXX
 SG_ PDM_counterMsg413 : 0|4@1+ (1,0) [0|15] "" Vector__XXX

BO_ 412 PDM_412: 8 PDM
 SG_ PDM_dataVoltMin : 48|16@1- (0.001,0) [-32.768|32.767] "V" Vector__XXX
 SG_ PDM_dataVoltMax : 32|16@1- (0.001,0) [-32.768|32.767] "V" Vector__XXX
 SG_ PDM_dataVoltAvg : 16|16@1- (0.001,0) [-32.768|32.767] "V" Vector__XXX
 SG_ PDM_counterMsg412 : 0|4@1+ (1,0) [0|15] "" Vector__XXX

BO_ 411 PDM_411: 8 PDM
 SG_ PDM_glvVoltMin : 48|16@1- (0.001,0) [-32.768|32.767] "V" Vector__XXX
 SG_ PDM_glvVoltMax : 32|16@1- (0.001,0) [-32.768|32.767] "V" Vector__XXX
 SG_ PDM_glvVoltAvg : 16|16@1- (0.001,0) [-32.768|32.767] "V" Vector__XXX
 SG_ PDM_counterMsg411 : 0|4@1+ (1,0) [0|15] "" Vector__XXX

BO_ 410 PDM_410: 8 PDM
 SG_ PDM_uptime : 0|32@1+ (1,0) [0|4294967295] "ms" Vector__XXX

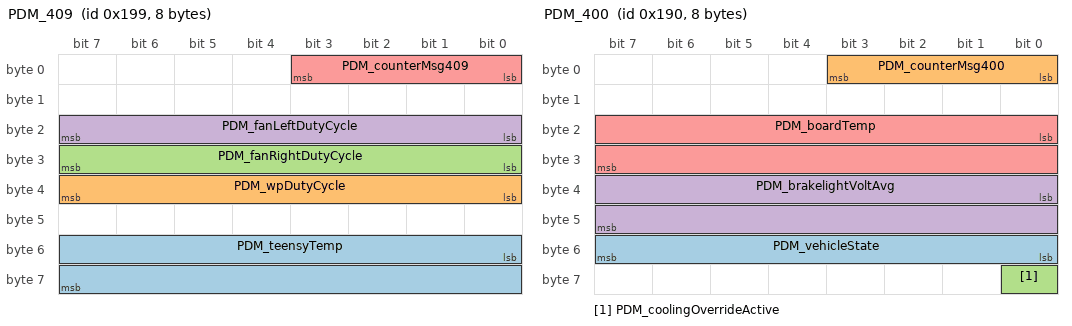
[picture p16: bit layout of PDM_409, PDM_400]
BO_ 409 PDM_409: 8 PDM
 SG_ PDM_teensyTemp : 48|16@1- (0.1,0) [-5|100] "degC" Vector__XXX
 SG_ PDM_wpDutyCycle : 32|8@1+ (1,0) [0|100] "%" Vector__XXX
 SG_ PDM_fanRightDutyCycle : 24|8@1+ (1,0) [0|100] "%" Vector__XXX
 SG_ PDM_fanLeftDutyCycle : 16|8@1+ (1,0) [0|100] "%" Vector__XXX
 SG_ PDM_counterMsg409 : 0|4@1+ (1,0) [0|15] "" Vector__XXX

BO_ 408 PDM_408: 8 PDM
 SG_ PDM_wpVoltMin : 48|16@1- (0.001,0) [-32.768|32.767] "V" Vector__XXX
 SG_ PDM_wpVoltMax : 32|16@1- (0.001,0) [-32.768|32.767] "V" Vector__XXX
 SG_ PDM_wpVoltAvg : 16|16@1- (0.001,0) [-32.768|32.767] "V" Vector__XXX
 SG_ PDM_counterMsg408 : 0|4@1+ (1,0) [0|15] "" Vector__XXX

BO_ 407 PDM_407: 8 PDM
 SG_ PDM_wpCurrentMin : 48|16@1- (0.01,0) [-327.68|327.67] "A" Vector__XXX
 SG_ PDM_wpCurrentMax : 32|16@1- (0.01,0) [-327.68|327.67] "A" Vector__XXX
 SG_ PDM_wpCurrentAvg : 16|16@1- (0.01,0) [-327.68|327.67] "A" Vector__XXX
 SG_ PDM_counterMsg407 : 0|4@1+ (1,0) [0|15] "" Vector__XXX

BO_ 406 PDM_406: 8 PDM
 SG_ PDM_fanLeftVoltMin : 48|16@1- (0.001,0) [-32.768|32.767] "V" Vector__XXX
 SG_ PDM_fanLeftVoltMax : 32|16@1- (0.001,0) [-32.768|32.767] "V" Vector__XXX
 SG_ PDM_fanLeftVoltAvg : 16|16@1- (0.001,0) [-32.768|32.767] "V" Vector__XXX
 SG_ PDM_counterMsg406 : 0|4@1+ (1,0) [0|15] "" Vector__XXX

BO_ 405 PDM_405: 8 PDM
 SG_ PDM_fanLeftCurrentMin : 48|16@1- (0.01,0) [-327.68|327.67] "A" Vector__XXX
 SG_ PDM_fanLeftCurrentMax : 32|16@1- (0.01,0) [-327.68|327.67] "A" Vector__XXX
 SG_ PDM_fanLeftCurrentAvg : 16|16@1- (0.01,0) [-327.68|327.67] "A" Vector__XXX
 SG_ PDM_counterMsg405 : 0|4@1+ (1,0) [0|15] "" Vector__XXX

BO_ 404 PDM_404: 8 PDM
 SG_ PDM_fanRightVoltMin : 48|16@1- (0.001,0) [-32.768|32.767] "V" Vector__XXX
 SG_ PDM_fanRightVoltMax : 32|16@1- (0.001,0) [-32.768|32.767] "V" Vector__XXX
 SG_ PDM_fanRightVoltAvg : 16|16@1- (0.001,0) [-32.768|32.767] "V" Vector__XXX
 SG_ PDM_counterMsg404 : 0|4@1+ (1,0) [0|15] "" Vector__XXX

BO_ 403 PDM_403: 8 PDM
 SG_ PDM_fanRightCurrentMin : 48|16@1- (0.01,0) [-327.68|327.67] "A" Vector__XXX
 SG_ PDM_fanRightCurrentMax : 32|16@1- (0.01,0) [-327.68|327.67] "A" Vector__XXX
 SG_ PDM_fanRightCurrentAvg : 16|16@1- (0.01,0) [-327.68|327.67] "A" Vector__XXX
 SG_ PDM_counterMsg403 : 0|4@1+ (1,0) [0|15] "" Vector__XXX

BO_ 402 PDM_402: 8 PDM
 SG_ PDM_pdmVoltMin : 48|16@1- (0.001,0) [-32.768|32.767] "V" Vector__XXX
 SG_ PDM_pdmVoltMax : 32|16@1- (0.001,0) [-32.768|32.767] "V" Vector__XXX
 SG_ PDM_pdmVoltAvg : 16|16@1- (0.001,0) [-32.768|32.767] "V" Vector__XXX
 SG_ PDM_counterMsg402 : 0|4@1+ (1,0) [0|15] "" Vector__XXX

BO_ 401 PDM_401: 8 PDM
 SG_ PDM_pdmCurrentMin : 48|16@1- (0.01,0) [-327.68|327.67] "A" Vector__XXX
 SG_ PDM_pdmCurrentMax : 32|16@1- (0.01,0) [-327.68|327.67] "A" Vector__XXX
 SG_ PDM_pdmCurrentAvg : 16|16@1- (0.01,0) [-327.68|327.67] "A" Vector__XXX
 SG_ PDM_counterMsg401 : 0|4@1+ (1,0) [0|15] "" Vector__XXX

BO_ 400 PDM_400: 8 PDM
 SG_ PDM_vehicleState : 48|8@1+ (1,0) [0|255] "" Vector__XXX
 SG_ PDM_counterMsg400 : 0|4@1+ (1,0) [0|15] "" Vector__XXX
 SG_ PDM_coolingOverrideActive : 56|1@1+ (1,0) [0|1] "" Vector__XXX
 SG_ PDM_brakelightVoltAvg : 32|16@1- (0.001,0) [-32.768|32.767] "V" Vector__XXX
 SG_ PDM_boardTemp : 16|16@1- (0.1,0) [-5|100] "degC" Vector__XXX

BO_ 215 BMS_215: 8 BMS
 SG_ BMS_rollingCounter215 : 0|8@1+ (1,0) [0|255] "" Vector__XXX
 SG_ BMS_relayState : 16|16@1+ (1,0) [0|65535] "" Vector__XXX
 SG_ BMS_failsafeStatus : 32|16@1+ (1,0) [0|65535] "" Vector__XXX
 SG_ BMS_dtcStatus2 : 48|16@1+ (1,0) [0|65535] "" Vector__XXX

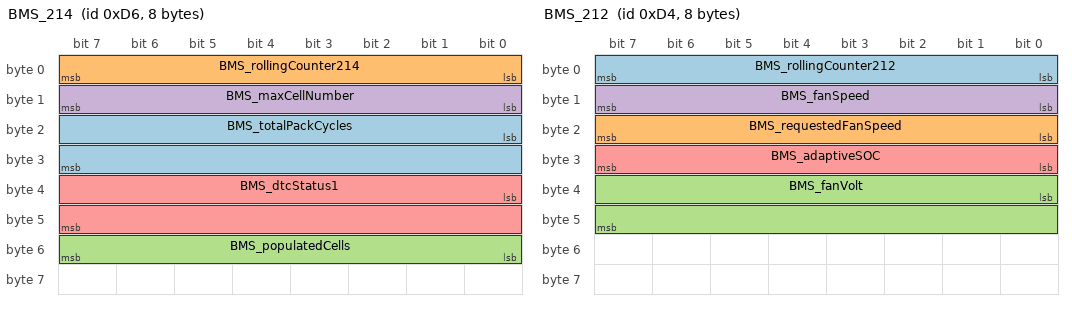
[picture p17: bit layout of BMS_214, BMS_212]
BO_ 214 BMS_214: 8 BMS
 SG_ BMS_totalPackCycles : 16|16@1+ (1,0) [0|65535] "Cycle" Vector__XXX
 SG_ BMS_rollingCounter214 : 0|8@1+ (1,0) [0|255] "" Vector__XXX
 SG_ BMS_populatedCells : 48|8@1+ (1,0) [0|255] "" Vector__XXX
 SG_ BMS_maxCellNumber : 8|8@1+ (1,0) [0|255] "" Vector__XXX
 SG_ BMS_dtcStatus1 : 32|16@1+ (1,0) [0|65535] "" Vector__XXX

BO_ 213 BMS_213: 8 BMS
 SG_ BMS_rollingCounter213 : 0|8@1+ (1,0) [0|255] "" Vector__XXX
 SG_ BMS_currLimStatus : 48|16@1+ (1,0) [0|65535] "" Vector__XXX
 SG_ BMS_adaptiveTotalCapacity : 16|16@1- (0.1,0) [-3276.8|3276.7] "Ahr" Vector__XXX
 SG_ BMS_adaptiveAmphours : 32|16@1- (0.1,0) [-3276.8|3276.7] "Ahr" Vector__XXX

BO_ 212 BMS_212: 8 BMS
 SG_ BMS_rollingCounter212 : 0|8@1+ (1,0) [0|255] "" Vector__XXX
 SG_ BMS_requestedFanSpeed : 16|8@1+ (1,0) [0|6] "" Vector__XXX
 SG_ BMS_fanVolt : 32|16@1- (0.01,0) [-327.68|327.67] "V" Vector__XXX
 SG_ BMS_fanSpeed : 8|8@1+ (1,0) [0|6] "" Vector__XXX
 SG_ BMS_adaptiveSOC : 24|8@1- (0.5,0) [0|100] "%" Vector__XXX

BO_ 211 BMS_211: 8 BMS
 SG_ BMS_rollingCounter211 : 0|8@1+ (1,0) [0|255] "" Vector__XXX
 SG_ BMS_maxPackDCL : 16|16@1- (1,0) [-32768|32767] "A" Vector__XXX
 SG_ BMS_maxPackCCL : 32|16@1- (1,0) [-32768|32767] "A" Vector__XXX
 SG_ BMS_avgPackCurr : 48|16@1- (0.1,0) [-3276.8|3276.7] "A" Vector__XXX

BO_ 210 BMS_210: 8 BMS
 SG_ BMS_rollingCounter210 : 0|8@1+ (1,0) [0|255] "" Vector__XXX
 SG_ BMS_packOpenVolt : 48|16@1- (0.1,0) [-3276.8|3276.7] "V" Vector__XXX
 SG_ BMS_packDischargeCurrLimkW : 32|16@1- (0.1,0) [-3276.8|3276.7] "kW" Vector__XXX
 SG_ BMS_packDischargeCurrLim : 16|16@1- (1,0) [-32768|32767] "A" Vector__XXX

BO_ 209 BMS_209: 8 BMS
 SG_ BMS_totalPackADC : 48|16@1- (0.1,0) [-3276.8|3276.7] "V" Vector__XXX
 SG_ BMS_rollingCounter209 : 0|8@1+ (1,0) [0|255] "" Vector__XXX
 SG_ BMS_packChargeCurrLimkW : 32|16@1- (0.1,0) [-3276.8|3276.7] "kW" Vector__XXX
 SG_ BMS_packChargeCurrLim : 16|16@1- (1,0) [-32768|32767] "A" Vector__XXX

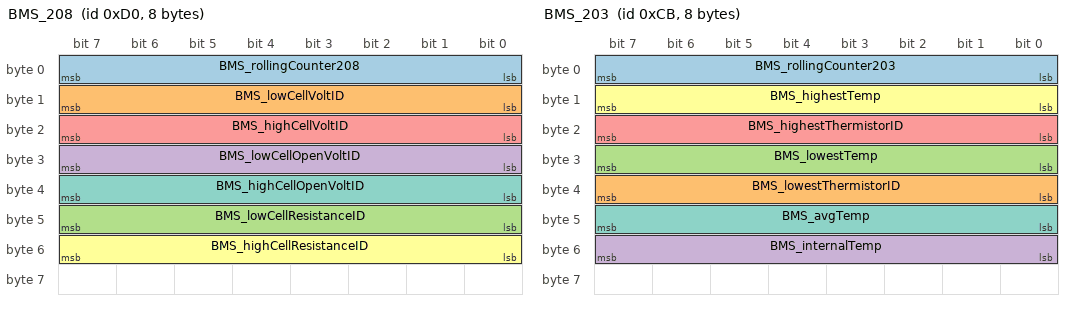
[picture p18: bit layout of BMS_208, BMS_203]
BO_ 208 BMS_208: 8 BMS
 SG_ BMS_rollingCounter208 : 0|8@1+ (1,0) [0|255] "" Vector__XXX
 SG_ BMS_lowCellVoltID : 8|8@1+ (1,0) [1|180] "" Vector__XXX
 SG_ BMS_lowCellResistanceID : 40|8@1+ (1,0) [1|180] "" Vector__XXX
 SG_ BMS_lowCellOpenVoltID : 24|8@1+ (1,0) [1|180] "" Vector__XXX
 SG_ BMS_highCellVoltID : 16|8@1+ (1,0) [1|180] "" Vector__XXX
 SG_ BMS_highCellResistanceID : 48|8@1+ (1,0) [1|180] "" Vector__XXX
 SG_ BMS_highCellOpenVoltID : 32|8@1+ (1,0) [1|180] "" Vector__XXX

BO_ 207 BMS_207: 8 BMS
 SG_ BMS_rollingCounter207 : 0|8@1+ (1,0) [0|255] "" Vector__XXX
 SG_ BMS_pwrInputVolt : 48|16@1- (0.1,0) [-3276.8|3276.7] "V" Vector__XXX
 SG_ BMS_minCellVolt : 32|16@1- (0.0001,0) [-3.2768|3.2767] "V" Vector__XXX
 SG_ BMS_maxCellVolt : 16|16@1- (0.0001,0) [-3.2768|3.2767] "V" Vector__XXX

BO_ 206 BMS_206: 8 BMS
 SG_ BMS_rollingCounter206 : 0|8@1+ (1,0) [0|255] "" Vector__XXX
 SG_ BMS_lowCellInternalResistance : 16|16@1- (0.01,0) [-327.68|327.67] "mOhm" Vector__XXX
 SG_ BMS_highCellInternalResistance : 32|16@1- (0.01,0) [-327.68|327.67] "mOhm" Vector__XXX
 SG_ BMS_avgCellInternalResistance : 48|16@1- (0.01,0) [-327.68|327.67] "mOhm" Vector__XXX

BO_ 205 BMS_205: 8 BMS
 SG_ BMS_rollingCounter205 : 0|8@1+ (1,0) [0|255] "" Vector__XXX
 SG_ BMS_lowCellOpenVolt : 16|16@1- (0.0001,0) [-3.2768|3.2767] "V" Vector__XXX
 SG_ BMS_highCellOpenVolt : 32|16@1- (0.0001,0) [-3.2768|3.2767] "V" Vector__XXX
 SG_ BMS_avgCellOpenVolt : 48|16@1- (0.0001,0) [-3.2768|3.2767] "V" Vector__XXX

BO_ 204 BMS_204: 8 BMS
 SG_ BMS_rollingCounter204 : 0|8@1+ (1,0) [0|255] "" Vector__XXX
 SG_ BMS_lowCellVolt : 16|16@1- (0.0001,0) [-3.2768|3.2767] "V" Vector__XXX
 SG_ BMS_highCellVolt : 32|16@1- (0.0001,0) [-3.2768|3.2767] "V" Vector__XXX
 SG_ BMS_avgCellVolt : 48|16@1- (0.0001,0) [-3.2768|3.2767] "V" Vector__XXX

BO_ 203 BMS_203: 8 BMS
 SG_ BMS_rollingCounter203 : 0|8@1+ (1,0) [0|255] "" Vector__XXX
 SG_ BMS_lowestThermistorID : 32|8@1+ (1,0) [1|180] "" Vector__XXX
 SG_ BMS_lowestTemp : 24|8@1- (1,0) [-5|100] "degC" Vector__XXX
 SG_ BMS_internalTemp : 48|8@1- (1,0) [-5|100] "degC" Vector__XXX
 SG_ BMS_highestThermistorID : 16|8@1+ (1,0) [1|180] "" Vector__XXX
 SG_ BMS_highestTemp : 8|8@1- (1,0) [-5|100] "degC" Vector__XXX
 SG_ BMS_avgTemp : 40|8@1- (1,0) [-5|100] "degC" Vector__XXX

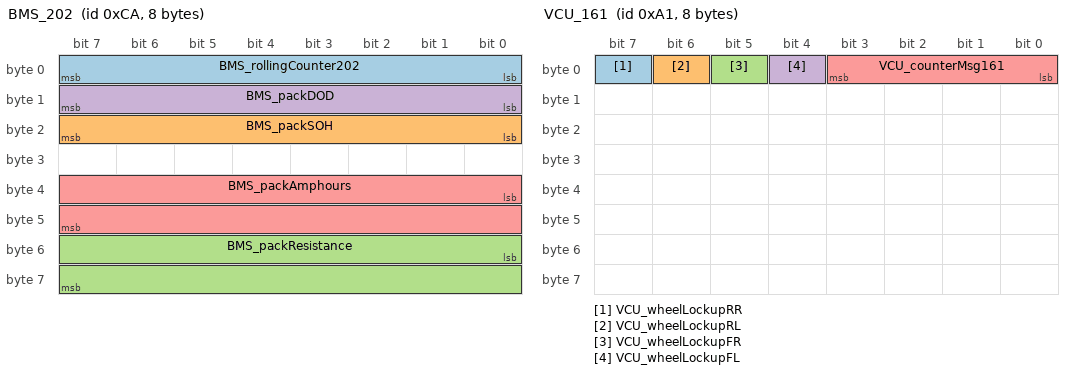
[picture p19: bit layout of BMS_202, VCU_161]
BO_ 202 BMS_202: 8 BMS
 SG_ BMS_rollingCounter202 : 0|8@1+ (1,0) [0|255] "" Vector__XXX
 SG_ BMS_packSOH : 16|8@1- (1,0) [0|100] "%" Vector__XXX
 SG_ BMS_packResistance : 48|16@1- (1,0) [-32768|32767] "mOhm" Vector__XXX
 SG_ BMS_packDOD : 8|8@1- (0.5,0) [0|100] "%" Vector__XXX
 SG_ BMS_packAmphours : 32|16@1- (0.1,0) [-3276.8|3276.7] "Ahr" Vector__XXX

BO_ 201 BMS_201: 8 BMS
 SG_ BMS_rollingCounter201 : 0|8@1+ (1,0) [0|255] "" Vector__XXX
 SG_ BMS_packSummedVolt : 16|16@1- (0.01,0) [-327.68|327.67] "V" Vector__XXX
 SG_ BMS_minPackVolt : 48|16@1- (0.1,0) [-3276.8|3276.7] "V" Vector__XXX
 SG_ BMS_maxPackVolt : 32|16@1- (0.1,0) [-3276.8|3276.7] "V" Vector__XXX

BO_ 200 BMS_200: 8 BMS
 SG_ BMS_rollingCounter200 : 0|8@1+ (1,0) [0|255] "" Vector__XXX
 SG_ BMS_packVolt : 32|16@1- (0.1,0) [-3276.8|3276.7] "V" Vector__XXX
 SG_ BMS_packSOC : 48|8@1- (0.5,0) [0|100] "%" Vector__XXX
 SG_ BMS_packCurr : 16|16@1- (0.1,0) [-3276.8|3276.7] "A" Vector__XXX

BO_ 161 VCU_161: 8 VCU
 SG_ VCU_wheelLockupRR : 7|1@1+ (1,0) [0|1] "" Vector__XXX
 SG_ VCU_wheelLockupRL : 6|1@1+ (1,0) [0|1] "" Vector__XXX
 SG_ VCU_wheelLockupFR : 5|1@1+ (1,0) [0|1] "" Vector__XXX
 SG_ VCU_wheelLockupFL : 4|1@1+ (1,0) [0|1] "" Vector__XXX
 SG_ VCU_counterMsg161 : 0|4@1+ (1,0) [0|15] "" Vector__XXX

BO_ 160 VCU_160: 8 VCU
 SG_ VCU_tcTorqueReduction : 16|16@1- (0.1,0) [0|75] "%" Vector__XXX
 SG_ VCU_tcSlipAimValue : 48|16@1- (0.1,0) [-3276.8|3276.7] "" Vector__XXX
 SG_ VCU_tcSlipAimError : 32|16@1- (0.1,0) [-3276.8|3276.7] "" Vector__XXX
 SG_ VCU_counterMsg160 : 0|4@1+ (1,0) [0|15] "" Vector__XXX

BO_ 159 VCU_159: 8 VCU
 SG_ VCU_counterMsg159 : 0|4@1+ (1,0) [0|15] "" Vector__XXX
 SG_ VCU_brakePressureR : 32|16@1- (0.1,0) [0|2000] "psi" Vector__XXX
 SG_ VCU_brakePressureF : 16|16@1- (0.1,0) [0|2000] "psi" Vector__XXX
 SG_ VCU_brakeBias : 48|16@1- (0.1,0) [0|100] "%" Vector__XXX

BO_ 158 VCU_158: 8 VCU
 SG_ VCU_suspensionTravelFR : 32|16@1- (0.001,0) [-4|4] "in" Vector__XXX
 SG_ VCU_suspensionTravelFL : 16|16@1- (0.001,0) [-4|4] "in" Vector__XXX
 SG_ VCU_counterMsg158 : 0|4@1+ (1,0) [0|15] "" Vector__XXX

BO_ 164 VCU_164: 8 VCU
 SG_ VCU_flowRateMotorIn : 16|16@1- (0.1,0) [0|20] "Lpm" Vector__XXX
 SG_ VCU_flowRateInverterOut : 48|16@1- (0.1,0) [0|20] "Lpm" Vector__XXX
 SG_ VCU_flowRateInverterIn : 32|16@1- (0.1,0) [0|20] "Lpm" Vector__XXX
 SG_ VCU_counterMsg162 : 0|4@1+ (1,0) [0|15] "" Vector__XXX

BO_ 157 VCU_157: 8 VCU
 SG_ VCU_tireTempRRO : 48|16@1- (0.1,0) [0|100] "degC" Vector__XXX
 SG_ VCU_tireTempRRM : 32|16@1- (0.1,0) [0|100] "degC" Vector__XXX
 SG_ VCU_tireTempRRI : 16|16@1- (0.1,0) [0|100] "degC" Vector__XXX
 SG_ VCU_counterMsg157 : 0|4@1+ (1,0) [0|15] "" Vector__XXX

BO_ 156 VCU_156: 8 VCU
 SG_ VCU_tireTempRLO : 48|16@1- (0.1,0) [0|100] "degC" Vector__XXX
 SG_ VCU_tireTempRLM : 32|16@1- (0.1,0) [0|100] "degC" Vector__XXX
 SG_ VCU_tireTempRLI : 16|16@1- (0.1,0) [0|100] "degC" Vector__XXX
 SG_ VCU_counterMsg156 : 0|4@1+ (1,0) [0|15] "" Vector__XXX

BO_ 155 VCU_155: 8 VCU
 SG_ VCU_rotorTempRR : 32|16@1- (0.1,0) [0|1000] "degC" Vector__XXX
 SG_ VCU_rotorTempRL : 16|16@1- (0.1,0) [0|1000] "degC" Vector__XXX
 SG_ VCU_counterMsg155 : 0|4@1+ (1,0) [0|15] "" Vector__XXX

BO_ 154 VCU_154: 8 VCU
 SG_ VCU_suspensionTravelRR : 32|16@1- (0.001,0) [-4|4] "in" Vector__XXX
 SG_ VCU_suspensionTravelRL : 16|16@1- (0.001,0) [-4|4] "in" Vector__XXX
 SG_ VCU_counterMsg154 : 0|4@1+ (1,0) [0|15] "" Vector__XXX

BO_ 153 VCU_153: 8 VCU
 SG_ VCU_tireTempFRO : 48|16@1- (0.1,0) [0|100] "degC" Vector__XXX
 SG_ VCU_tireTempFRM : 32|16@1- (0.1,0) [0|100] "degC" Vector__XXX
 SG_ VCU_tireTempFRI : 16|16@1- (0.1,0) [0|100] "degC" Vector__XXX
 SG_ VCU_counterMsg153 : 0|4@1+ (1,0) [0|15] "" Vector__XXX

BO_ 152 VCU_152: 8 VCU
 SG_ VCU_tireTempFLO : 48|16@1- (0.1,0) [0|100] "degC" Vector__XXX
 SG_ VCU_tireTempFLM : 32|16@1- (0.1,0) [0|100] "degC" Vector__XXX
 SG_ VCU_tireTempFLI : 16|16@1- (0.1,0) [0|100] "degC" Vector__XXX
 SG_ VCU_counterMsg152 : 0|4@1+ (1,0) [0|15] "" Vector__XXX

BO_ 151 VCU_151: 8 VCU
 SG_ VCU_rotorTempFR : 32|16@1- (0.1,0) [0|1000] "degC" Vector__XXX
 SG_ VCU_rotorTempFL : 16|16@1- (0.1,0) [0|1000] "degC" Vector__XXX
 SG_ VCU_counterMsg151 : 0|4@1+ (1,0) [0|15] "" Vector__XXX

BO_ 150 VCU_150: 8 VCU
 SG_ VCU_throttlePosition : 16|16@1- (0.1,0) [0|100] "%" Vector__XXX
 SG_ VCU_tcSet : 48|8@1+ (1,0) [0|11] "" Vector__XXX
 SG_ VCU_counterMsg150 : 0|4@1+ (1,0) [0|15] "" Vector__XXX
 SG_ VCU_brakePosition : 32|16@1- (0.1,0) [0|100] "%" Vector__XXX

CM_ BO_ 3221225472 "This is a message for not used signals, created by Vector CANdb++ DBC OLE DB Provider.";
CM_ SG_ 3221225472 VCU_counterMsg172 "Counter Message 172
";
CM_ SG_ 3221225472 VCU_groundSpeed "Ground Speed
";
CM_ SG_ 3221225472 VCU_groundSpeedLeft "Left Ground Speed
";
CM_ SG_ 3221225472 VCU_groundSpeedRight "Right Ground Speed
";
CM_ SG_ 3221225472 VCU_driveSpeed "Drive Speed
";
CM_ SG_ 3221225472 VCU_driveSpeedLeft "Left Drive Speed
";
CM_ SG_ 3221225472 VCU_driveSpeedRight "Right Drive Speed
";
CM_ SG_ 173 VCU_driveSpeed "Drive Speed
";
CM_ SG_ 173 VCU_groundSpeed "Ground speed
";
CM_ SG_ 173 VCU_counterMsg173 "Counter Message 173
";
CM_ SG_ 172 VCU_brakePosR "Brake position of the rear sensor
";
CM_ SG_ 172 VCU_brakePosF "Brake position of the front sensor
";
CM_ SG_ 172 VCU_counterMsg172 "Counter Message 172
";
CM_ SG_ 171 VCU_throttlePos2 "Throttle position of sensor 2
";
CM_ SG_ 171 VCU_throttlePos1 "Throttle position of sensor 1
";
CM_ SG_ 171 VCU_counterMsg171 "Counter Message 171
";
CM_ SG_ 170 VCU_roadSingleWheelAngle "Road wheel angle (no ackermann)
";
CM_ SG_ 170 VCU_roadWheelAngleR "Road wheel angle of the right wheel
";
CM_ SG_ 170 VCU_roadWheelAngleL "Road wheel angle of the left wheel
";
CM_ SG_ 170 VCU_counterMsg170 "Counter Message 170
";
CM_ SG_ 169 VCU_tsSwitch "1 = active, 0 = inactive
";
CM_ SG_ 169 VCU_coolSwitch "1 = active, 0 = inactive
";
CM_ SG_ 169 VCU_pwrDownSwitch "1 = active, 0 = inactive
";
CM_ SG_ 169 VCU_pwrUpSwitch "1 = active, 0 = inactive
";
CM_ SG_ 169 VCU_startSwitch "1 = active, 0 = inactive
";
CM_ SG_ 169 VCU_mainPlusState "1 = active, 0 = inactive
";
CM_ SG_ 169 VCU_mainMinusState "1 = active, 0 = inactive
";
CM_ SG_ 169 VCU_dischargeState "1 = active, 0 = inactive
";
CM_ SG_ 169 VCU_prechargeState "1 = active, 0 = inactive
";
CM_ SG_ 169 VCU_rtdState "1 = active, 0 = inactive
";
CM_ SG_ 169 VCU_counterMsg169 "Counter Message 169
";
CM_ SG_ 168 VCU_latVehicleSpeed "Lateral vehicle speed
";
CM_ SG_ 168 VCU_wheelSpeedRR "RR wheel speed
";
CM_ SG_ 168 VCU_wheelSpeedRL "RL wheel speed 
";
CM_ SG_ 168 VCU_counterMsg168 "Counter Message 168
";
CM_ SG_ 167 VCU_longVehicleSpeed "Longitudinal vehicle speed
";
CM_ SG_ 167 VCU_wheelSpeedFR "FR wheel speed
";
CM_ SG_ 167 VCU_wheelSpeedFL "FL wheel speed 
";
CM_ SG_ 167 VCU_counterMsg167 "Counter Message 167
";
CM_ SG_ 166 VCU_cellSegment8FanPct "Fan duty for segment 8
";
CM_ SG_ 166 VCU_cellSegment7FanPct "Fan duty for segment 7
";
CM_ SG_ 166 VCU_cellSegment6FanPct "Fan duty for segment 6
";
CM_ SG_ 166 VCU_cellSegment5FanPct "Fan duty for segment 5
";
CM_ SG_ 166 VCU_counterMsg166 "Counter Message 166
";
CM_ SG_ 165 VCU_cellSegment4FanPct "Fan duty for segment 4
";
CM_ SG_ 165 VCU_cellSegment3FanPct "Fan duty for segment 3
";
CM_ SG_ 165 VCU_cellSegment2FanPct "Fan duty for segment 2
";
CM_ SG_ 165 VCU_cellSegment1FanPct "Fan duty for segment 1
";
CM_ SG_ 165 VCU_counterMsg165 "Counter Message 165
";
CM_ SG_ 2565799815 STMM_seg8Constant3 "Constant 3 (0x90)
";
CM_ SG_ 2565799815 STMM_seg8Constant2 "Constant 2 (0x1E)
";
CM_ SG_ 2565799815 STMM_seg8Constant1 "Constant 1 (0x40)
";
CM_ SG_ 2565799815 STMM_seg8ThermModuleNumber "Thermistor Module Number << 3 (Default = 0x00)
";
CM_ SG_ 2565799815 STMM_seg8BMSTargetAddress "BMS Target Address (0xF3 default)
";
CM_ SG_ 2565799815 STMM_seg8AddressClaim "Unique identifier for J1939 compatible address claim (Default value is: 0xF3 00 80)
";
CM_ SG_ 2565799814 STMM_seg7Constant3 "Constant 3 (0x90)
";
CM_ SG_ 2565799814 STMM_seg7Constant2 "Constant 2 (0x1E)
";
CM_ SG_ 2565799814 STMM_seg7Constant1 "Constant 1 (0x40)
";
CM_ SG_ 2565799814 STMM_seg7ThermModuleNumber "Thermistor Module Number << 3 (Default = 0x00)
";
CM_ SG_ 2565799814 STMM_seg7BMSTargetAddress "BMS Target Address (0xF3 default)
";
CM_ SG_ 2565799814 STMM_seg7AddressClaim "Unique identifier for J1939 compatible address claim (Default value is: 0xF3 00 80)
";
CM_ SG_ 2565799813 STMM_seg6Constant3 "Constant 3 (0x90)
";
CM_ SG_ 2565799813 STMM_seg6Constant2 "Constant 2 (0x1E)
";
CM_ SG_ 2565799813 STMM_seg6Constant1 "Constant 1 (0x40)
";
CM_ SG_ 2565799813 STMM_seg6ThermModuleNumber "Thermistor Module Number << 3 (Default = 0x00)
";
CM_ SG_ 2565799813 STMM_seg6BMSTargetAddress "BMS Target Address (0xF3 default)
";
CM_ SG_ 2565799813 STMM_seg6AddressClaim "Unique identifier for J1939 compatible address claim (Default value is: 0xF3 00 80)
";
CM_ SG_ 2565799812 STMM_seg5Constant3 "Constant 3 (0x90)
";
CM_ SG_ 2565799812 STMM_seg5Constant2 "Constant 2 (0x1E)
";
CM_ SG_ 2565799812 STMM_seg5Constant1 "Constant 1 (0x40)
";
CM_ SG_ 2565799812 STMM_seg5ThermModuleNumber "Thermistor Module Number << 3 (Default = 0x00)
";
CM_ SG_ 2565799812 STMM_seg5BMSTargetAddress "BMS Target Address (0xF3 default)
";
CM_ SG_ 2565799812 STMM_seg5AddressClaim "Unique identifier for J1939 compatible address claim (Default value is: 0xF3 00 80)
";
CM_ SG_ 2565799811 STMM_seg4Constant3 "Constant 3 (0x90)
";
CM_ SG_ 2565799811 STMM_seg4Constant2 "Constant 2 (0x1E)
";
CM_ SG_ 2565799811 STMM_seg4Constant1 "Constant 1 (0x40)
";
CM_ SG_ 2565799811 STMM_seg4ThermModuleNumber "Thermistor Module Number << 3 (Default = 0x00)
";
CM_ SG_ 2565799811 STMM_seg4BMSTargetAddress "BMS Target Address (0xF3 default)
";
CM_ SG_ 2565799811 STMM_seg4AddressClaim "Unique identifier for J1939 compatible address claim (Default value is: 0xF3 00 80)
";
CM_ SG_ 2565799810 STMM_seg3Constant3 "Constant 3 (0x90)
";
CM_ SG_ 2565799810 STMM_seg3Constant2 "Constant 2 (0x1E)
";
CM_ SG_ 2565799810 STMM_seg3Constant1 "Constant 1 (0x40)
";
CM_ SG_ 2565799810 STMM_seg3ThermModuleNumber "Thermistor Module Number << 3 (Default = 0x00)
";
CM_ SG_ 2565799810 STMM_seg3BMSTargetAddress "BMS Target Address (0xF3 default)
";
CM_ SG_ 2565799810 STMM_seg3AddressClaim "Unique identifier for J1939 compatible address claim (Default value is: 0xF3 00 80)
";
CM_ SG_ 2565799809 STMM_seg2Constant3 "Constant 3 (0x90)
";
CM_ SG_ 2565799809 STMM_seg2Constant2 "Constant 2 (0x1E)
";
CM_ SG_ 2565799809 STMM_seg2Constant1 "Constant 1 (0x40)
";
CM_ SG_ 2565799809 STMM_seg2ThermModuleNumber "Thermistor Module Number << 3 (Default = 0x00)
";
CM_ SG_ 2565799809 STMM_seg2BMSTargetAddress "BMS Target Address (0xF3 default)
";
CM_ SG_ 2565799809 STMM_seg2AddressClaim "Unique identifier for J1939 compatible address claim (Default value is: 0xF3 00 80)
";
CM_ SG_ 2565799808 STMM_seg1Constant3 "Constant 3 (0x90)
";
CM_ SG_ 2565799808 STMM_seg1Constant2 "Constant 2 (0x1E)
";
CM_ SG_ 2565799808 STMM_seg1Constant1 "Constant 1 (0x40)
";
CM_ SG_ 2565799808 STMM_seg1ThermModuleNumber "Thermistor Module Number << 3 (Default = 0x00)
";
CM_ SG_ 2565799808 STMM_seg1BMSTargetAddress "BMS Target Address (0xF3 default)
";
CM_ SG_ 2565799808 STMM_seg1AddressClaim "Unique identifier for J1939 compatible address claim (Default value is: 0xF3 00 80)
";
CM_ SG_ 2553869191 STMM_seg8ThermIDLow "Lowest thermistor ID on the module
";
CM_ SG_ 2553869191 STMM_seg8ThermIDHigh "Highest thermistor ID on the module
";
CM_ SG_ 2553869191 STMM_seg8ThermValHigh "Highest thermistor value
";
CM_ SG_ 2553869191 STMM_seg8ThermValLow "Lowest thermistor value
";
CM_ SG_ 2553869191 STMM_seg8ThermID "Thermistor ID relative to this thermistor module
Thermistor ID relative to all configured thermistor modules
";
CM_ SG_ 2553869191 STMM_seg8ThermVal "Thermistor value
";
CM_ SG_ 2553869190 STMM_seg7ThermIDLow "Lowest thermistor ID on the module
";
CM_ SG_ 2553869190 STMM_seg7ThermIDHigh "Highest thermistor ID on the module
";
CM_ SG_ 2553869190 STMM_seg7ThermValHigh "Highest thermistor value
";
CM_ SG_ 2553869190 STMM_seg7ThermValLow "Lowest thermistor value
";
CM_ SG_ 2553869190 STMM_seg7ThermID "Thermistor ID relative to this thermistor module
Thermistor ID relative to all configured thermistor modules
";
CM_ SG_ 2553869190 STMM_seg7ThermVal "Thermistor value
";
CM_ SG_ 2553869189 STMM_seg6ThermIDLow "Lowest thermistor ID on the module
";
CM_ SG_ 2553869189 STMM_seg6ThermIDHigh "Highest thermistor ID on the module
";
CM_ SG_ 2553869189 STMM_seg6ThermValHigh "Highest thermistor value
";
CM_ SG_ 2553869189 STMM_seg6ThermValLow "Lowest thermistor value
";
CM_ SG_ 2553869189 STMM_seg6ThermID "Thermistor ID relative to this thermistor module
Thermistor ID relative to all configured thermistor modules
";
CM_ SG_ 2553869189 STMM_seg6ThermVal "Thermistor value
";
CM_ SG_ 2553869188 STMM_seg5ThermIDLow "Lowest thermistor ID on the module
";
CM_ SG_ 2553869188 STMM_seg5ThermIDHigh "Highest thermistor ID on the module
";
CM_ SG_ 2553869188 STMM_seg5ThermValHigh "Highest thermistor value
";
CM_ SG_ 2553869188 STMM_seg5ThermValLow "Lowest thermistor value
";
CM_ SG_ 2553869188 STMM_seg5ThermID "Thermistor ID relative to this thermistor module
Thermistor ID relative to all configured thermistor modules
";
CM_ SG_ 2553869188 STMM_seg5ThermVal "Thermistor value
";
CM_ SG_ 2553869187 STMM_seg4ThermIDLow "Lowest thermistor ID on the module
";
CM_ SG_ 2553869187 STMM_seg4ThermIDHigh "Highest thermistor ID on the module
";
CM_ SG_ 2553869187 STMM_seg4ThermValHigh "Highest thermistor value
";
CM_ SG_ 2553869187 STMM_seg4ThermValLow "Lowest thermistor value
";
CM_ SG_ 2553869187 STMM_seg4ThermID "Thermistor ID relative to this thermistor module
Thermistor ID relative to all configured thermistor modules
";
CM_ SG_ 2553869187 STMM_seg4ThermVal "Thermistor value
";
CM_ SG_ 2553869186 STMM_seg3ThermIDLow "Lowest thermistor ID on the module
";
CM_ SG_ 2553869186 STMM_seg3ThermIDHigh "Highest thermistor ID on the module
";
CM_ SG_ 2553869186 STMM_seg3ThermValHigh "Highest thermistor value
";
CM_ SG_ 2553869186 STMM_seg3ThermValLow "Lowest thermistor value
";
CM_ SG_ 2553869186 STMM_seg3ThermID "Thermistor ID relative to this thermistor module
Thermistor ID relative to all configured thermistor modules
";
CM_ SG_ 2553869186 STMM_seg3ThermVal "Thermistor value
";
CM_ SG_ 2553869185 STMM_seg2ThermIDLow "Lowest thermistor ID on the module
";
CM_ SG_ 2553869185 STMM_seg2ThermIDHigh "Highest thermistor ID on the module
";
CM_ SG_ 2553869185 STMM_seg2ThermValHigh "Highest thermistor value
";
CM_ SG_ 2553869185 STMM_seg2ThermValLow "Lowest thermistor value
";
CM_ SG_ 2553869185 STMM_seg2ThermID "Thermistor ID relative to this thermistor module
Thermistor ID relative to all configured thermistor modules
";
CM_ SG_ 2553869185 STMM_seg2ThermVal "Thermistor value
";
CM_ SG_ 2553869184 STMM_seg1ThermIDLow "Lowest thermistor ID on the module
";
CM_ SG_ 2553869184 STMM_seg1ThermIDHigh "Highest thermistor ID on the module
";
CM_ SG_ 2553869184 STMM_seg1ThermValHigh "Highest thermistor value
";
CM_ SG_ 2553869184 STMM_seg1ThermValLow "Lowest thermistor value
";
CM_ SG_ 2553869184 STMM_seg1ThermID "Thermistor ID relative to this thermistor module
Thermistor ID relative to all configured thermistor modules
";
CM_ SG_ 2553869184 STMM_seg1ThermVal "Thermistor value
";
CM_ SG_ 380 MM5_az "Acceleration Z Axis
";
CM_ SG_ 376 MM5_rollRate "Roll Rate
";
CM_ SG_ 376 MM5_ax "Acceleration X Axis
";
CM_ SG_ 372 MM5_yawRate "Yaw Rate
";
CM_ SG_ 372 MM5_ay "Acceleration Y Axis
";
CM_ SG_ 331 STMM_segmentTemp811 "Segment 8 module 11
";
CM_ SG_ 331 STMM_segmentTemp810 "Segment 8 module 10
";
CM_ SG_ 331 STMM_segmentTemp809 "Segment 8 module 9
";
CM_ SG_ 331 STMM_counterMsg331 "Counter Message 331
";
CM_ SG_ 330 STMM_segmentTemp808 "Segment 8 module 8
";
CM_ SG_ 330 STMM_segmentTemp807 "Segment 8 module 7
";
CM_ SG_ 330 STMM_segmentTemp806 "Segment 8 module 6
";
CM_ SG_ 330 STMM_counterMsg330 "Counter Message 330
";
CM_ SG_ 329 STMM_segmentTemp805 "Segment 8 module 5
";
CM_ SG_ 329 STMM_segmentTemp804 "Segment 8 module 4
";
CM_ SG_ 329 STMM_segmentTemp803 "Segment 8 module 3
";
CM_ SG_ 329 STMM_counterMsg329 "Counter Message 329
";
CM_ SG_ 328 STMM_segmentTemp802 "Segment 8 module 2
";
CM_ SG_ 328 STMM_segmentTemp801 "Segment 8 module 1
";
CM_ SG_ 328 STMM_segmentTemp800 "Segment 8 module 0
";
CM_ SG_ 328 STMM_counterMsg328 "Counter Message 328
";
CM_ SG_ 327 STMM_segmentTemp711 "Segment 7 module 11
";
CM_ SG_ 327 STMM_segmentTemp710 "Segment 7 module 10
";
CM_ SG_ 327 STMM_segmentTemp709 "Segment 7 module 9
";
CM_ SG_ 327 STMM_counterMsg327 "Counter Message 327
";
CM_ SG_ 326 STMM_segmentTemp708 "Segment 7 module 8
";
CM_ SG_ 326 STMM_segmentTemp707 "Segment 7 module 7
";
CM_ SG_ 326 STMM_segmentTemp706 "Segment 7 module 6
";
CM_ SG_ 326 STMM_counterMsg326 "Counter Message 326
";
CM_ SG_ 325 STMM_segmentTemp705 "Segment 7 module 5
";
CM_ SG_ 325 STMM_segmentTemp704 "Segment 7 module 4
";
CM_ SG_ 325 STMM_segmentTemp703 "Segment 7 module 3
";
CM_ SG_ 325 STMM_counterMsg325 "Counter Message 325
";
CM_ SG_ 324 STMM_segmentTemp701 "Segment 7 module 1
";
CM_ SG_ 324 STMM_segmentTemp700 "Segment 7 module 0
";
CM_ SG_ 324 STMM_counterMsg324 "Counter Message 324
";
CM_ SG_ 323 STMM_segmentTemp611 "Segment 6 module 11
";
CM_ SG_ 323 STMM_segmentTemp610 "Segment 6 module 10
";
CM_ SG_ 323 STMM_segmentTemp609 "Segment 6 module 9
";
CM_ SG_ 323 STMM_counterMsg323 "Counter Message 323
";
CM_ SG_ 322 STMM_segmentTemp608 "Segment 6 module 8
";
CM_ SG_ 322 STMM_segmentTemp607 "Segment 6 module 7
";
CM_ SG_ 322 STMM_segmentTemp606 "Segment 6 module 6
";
CM_ SG_ 322 STMM_counterMsg322 "Counter Message 322
";
CM_ SG_ 321 STMM_segmentTemp605 "Segment 6 module 5
";
CM_ SG_ 321 STMM_segmentTemp604 "Segment 6 module 4
";
CM_ SG_ 321 STMM_segmentTemp603 "Segment 6 module 3
";
CM_ SG_ 321 STMM_counterMsg321 "Counter Message 321
";
CM_ SG_ 320 STMM_segmentTemp602 "Segment 6 module 2
";
CM_ SG_ 320 STMM_segmentTemp601 "Segment 6 module 1
";
CM_ SG_ 320 STMM_segmentTemp600 "Segment 6 module 0
";
CM_ SG_ 320 STMM_counterMsg320 "Counter Message 320
";
CM_ SG_ 319 STMM_segmentTemp511 "Segment 5 module 11
";
CM_ SG_ 319 STMM_segmentTemp510 "Segment 5 module 10
";
CM_ SG_ 319 STMM_segmentTemp509 "Segment 5 module 9
";
CM_ SG_ 319 STMM_counterMsg319 "Counter Message 319
";
CM_ SG_ 318 STMM_segmentTemp508 "Segment 5 module 8
";
CM_ SG_ 318 STMM_segmentTemp507 "Segment 5 module 7
";
CM_ SG_ 318 STMM_segmentTemp506 "Segment 5 module 6
";
CM_ SG_ 318 STMM_counterMsg318 "Counter Message 318
";
CM_ SG_ 317 STMM_segmentTemp505 "Segment 5 module 5
";
CM_ SG_ 317 STMM_segmentTemp504 "Segment 5 module 4
";
CM_ SG_ 317 STMM_segmentTemp503 "Segment 5 module 3
";
CM_ SG_ 317 STMM_counterMsg317 "Counter Message 317
";
CM_ SG_ 316 STMM_segmentTemp502 "Segment 5 module 2
";
CM_ SG_ 316 STMM_segmentTemp501 "Segment 5 module 1
";
CM_ SG_ 316 STMM_segmentTemp500 "Segment 5 module 0
";
CM_ SG_ 316 STMM_counterMsg316 "Counter Message 316
";
CM_ SG_ 315 STMM_segmentTemp411 "Segment 4 module 11
";
CM_ SG_ 315 STMM_segmentTemp410 "Segment 4 module 10
";
CM_ SG_ 315 STMM_segmentTemp409 "Segment 4 module 9
";
CM_ SG_ 315 STMM_counterMsg315 "Counter Message 315
";
CM_ SG_ 314 STMM_segmentTemp408 "Segment 4 module 8
";
CM_ SG_ 314 STMM_segmentTemp407 "Segment 4 module 7
";
CM_ SG_ 314 STMM_segmentTemp406 "Segment 4 module 6
";
CM_ SG_ 314 STMM_counterMsg314 "Counter Message 314
";
CM_ SG_ 313 STMM_segmentTemp405 "Segment 4 module 5
";
CM_ SG_ 313 STMM_segmentTemp404 "Segment 4 module 4
";
CM_ SG_ 313 STMM_segmentTemp403 "Segment 4 module 3
";
CM_ SG_ 313 STMM_counterMsg313 "Counter Message 313
";
CM_ SG_ 312 STMM_segmentTemp402 "Segment 4 module 2
";
CM_ SG_ 312 STMM_segmentTemp401 "Segment 4 module 1
";
CM_ SG_ 312 STMM_segmentTemp400 "Segment 4 module 0
";
CM_ SG_ 312 STMM_counterMsg312 "Counter Message 312
";
CM_ SG_ 311 STMM_segmentTemp311 "Segment 3 module 11
";
CM_ SG_ 311 STMM_segmentTemp310 "Segment 3 module 10
";
CM_ SG_ 311 STMM_segmentTemp309 "Segment 3 module 9
";
CM_ SG_ 311 STMM_counterMsg311 "Counter Message 311
";
CM_ SG_ 310 STMM_segmentTemp308 "Segment 3 module 8
";
CM_ SG_ 310 STMM_segmentTemp307 "Segment 3 module 7
";
CM_ SG_ 310 STMM_segmentTemp306 "Segment 3 module 6
";
CM_ SG_ 310 STMM_counterMsg310 "Counter Message 310
";
CM_ SG_ 309 STMM_segmentTemp305 "Segment 3 module 5
";
CM_ SG_ 309 STMM_segmentTemp304 "Segment 3 module 4
";
CM_ SG_ 309 STMM_segmentTemp303 "Segment 3 module 3
";
CM_ SG_ 309 STMM_counterMsg309 "Counter Message 309
";
CM_ SG_ 308 STMM_segmentTemp302 "Segment 3 module 2
";
CM_ SG_ 308 STMM_segmentTemp301 "Segment 3 module 1
";
CM_ SG_ 308 STMM_segmentTemp300 "Segment 3 module 0
";
CM_ SG_ 308 STMM_counterMsg308 "Counter Message 308
";
CM_ SG_ 307 STMM_segmentTemp211 "Segment 2 module 11
";
CM_ SG_ 307 STMM_segmentTemp210 "Segment 2 module 10
";
CM_ SG_ 307 STMM_segmentTemp209 "Segment 2 module 9
";
CM_ SG_ 307 STMM_counterMsg307 "Counter Message 307
";
CM_ SG_ 306 STMM_segmentTemp208 "Segment 2 module 8
";
CM_ SG_ 306 STMM_segmentTemp207 "Segment 2 module 7
";
CM_ SG_ 306 STMM_segmentTemp206 "Segment 2 module 6
";
CM_ SG_ 306 STMM_counterMsg306 "Counter Message 306
";
CM_ SG_ 305 STMM_segmentTemp205 "Segment 2 module 5
";
CM_ SG_ 305 STMM_segmentTemp204 "Segment 2 module 4
";
CM_ SG_ 305 STMM_segmentTemp203 "Segment 2 module 3
";
CM_ SG_ 305 STMM_counterMsg305 "Counter Message 305
";
CM_ SG_ 304 STMM_segmentTemp202 "Segment 2 module 2
";
CM_ SG_ 304 STMM_segmentTemp201 "Segment 2 module 1
";
CM_ SG_ 304 STMM_segmentTemp200 "Segment 2 module 0
";
CM_ SG_ 304 STMM_counterMsg304 "Counter Message 304
";
CM_ SG_ 303 STMM_segmentTemp111 "Segment 1 module 11
";
CM_ SG_ 303 STMM_segmentTemp110 "Segment 1 module 10
";
CM_ SG_ 303 STMM_segmentTemp109 "Segment 1 module 9
";
CM_ SG_ 303 STMM_counterMsg303 "Counter Message 303
";
CM_ SG_ 302 STMM_segmentTemp108 "Segment 1 module 8
";
CM_ SG_ 302 STMM_segmentTemp107 "Segment 1 module 7
";
CM_ SG_ 302 STMM_segmentTemp106 "Segment 1 module 6
";
CM_ SG_ 302 STMM_counterMsg302 "Counter Message 302
";
CM_ SG_ 301 STMM_segmentTemp105 "Segment 1 module 5
";
CM_ SG_ 301 STMM_segmentTemp104 "Segment 1 module 4
";
CM_ SG_ 301 STMM_segmentTemp103 "Segment 1 module 3
";
CM_ SG_ 301 STMM_counterMsg301 "Counter Message 301
";
CM_ SG_ 300 STMM_segmentTemp102 "Segment 1 module 2
";
CM_ SG_ 300 STMM_segmentTemp101 "Segment 1 module 1
";
CM_ SG_ 300 STMM_segmentTemp100 "Segment 1 module 0
";
CM_ SG_ 300 STMM_counterMsg300 "Counter Message 300
";
CM_ SG_ 250 DD_teensyTemp "Teensy Board Temp
";
CM_ SG_ 250 DD_counterMsg250 "Counter Message 250";
CM_ SG_ 250 DD_boardTemp "Board Temp
";
CM_ SG_ 414 PDM_runtimeMinutes "Runtime Minutes
";
CM_ SG_ 414 PDM_runtimeHours "Runtime Hours
";
CM_ SG_ 414 PDM_counterMsg414 "Counter Message 414
";
CM_ SG_ 414 PDM_carMiles "Car Miles
";
CM_ SG_ 413 PDM_keepAliveVoltMin "Keep Alive Minimum Voltage
";
CM_ SG_ 413 PDM_keepAliveVoltMax "Keep Alive Maximum Voltage
";
CM_ SG_ 413 PDM_keepAliveVoltAvg "Keep Alive Average Voltage
";
CM_ SG_ 413 PDM_counterMsg413 "Counter Message 413
";
CM_ SG_ 412 PDM_dataVoltMin "Data Minimum Voltage
";
CM_ SG_ 412 PDM_dataVoltMax "Data Maximum Voltage
";
CM_ SG_ 412 PDM_dataVoltAvg "Data Average Voltage
";
CM_ SG_ 412 PDM_counterMsg412 "Counter Message 412
";
CM_ SG_ 411 PDM_glvVoltMin "GLV Minimum Voltage
";
CM_ SG_ 411 PDM_glvVoltMax "GLV Maximum Voltage
";
CM_ SG_ 411 PDM_glvVoltAvg "GLV Average Voltage
";
CM_ SG_ 411 PDM_counterMsg411 "Counter Message 411
";
CM_ SG_ 410 PDM_uptime "PDM Teensy Uptime
";
CM_ SG_ 409 PDM_teensyTemp "Teensy Board Temperature
";
CM_ SG_ 409 PDM_wpDutyCycle "Water Pump Duty Cycle
";
CM_ SG_ 409 PDM_fanRightDutyCycle "Right Fan Duty Cycle
";
CM_ SG_ 409 PDM_fanLeftDutyCycle "Left Fan Duty Cycle
";
CM_ SG_ 409 PDM_counterMsg409 "Counter Message 409
";
CM_ SG_ 408 PDM_wpVoltMin "Water Pump Minimum Voltage
";
CM_ SG_ 408 PDM_wpVoltMax "Water Pump Maximum Voltage
";
CM_ SG_ 408 PDM_wpVoltAvg "Water Pump Average Voltage
";
CM_ SG_ 408 PDM_counterMsg408 "Counter Message 408
";
CM_ SG_ 407 PDM_wpCurrentMin "Water Pump Minimum Current
";
CM_ SG_ 407 PDM_wpCurrentMax "Water Pump Maximum Current
";
CM_ SG_ 407 PDM_wpCurrentAvg "Water Pump Average Current
";
CM_ SG_ 407 PDM_counterMsg407 "Counter Message 407
";
CM_ SG_ 406 PDM_fanLeftVoltMin "Left Fan Minimum Voltage
";
CM_ SG_ 406 PDM_fanLeftVoltMax "Left Fan Maximum Voltage
";
CM_ SG_ 406 PDM_fanLeftVoltAvg "Left Fan Average Voltage
";
CM_ SG_ 406 PDM_counterMsg406 "Counter Message 406
";
CM_ SG_ 405 PDM_fanLeftCurrentMin "Left Fan Minimum Current
";
CM_ SG_ 405 PDM_fanLeftCurrentMax "Left Fan Maximum Current
";
CM_ SG_ 405 PDM_fanLeftCurrentAvg "Left Fan Average Current
";
CM_ SG_ 405 PDM_counterMsg405 "Counter Message 405
";
CM_ SG_ 404 PDM_fanRightVoltMin "Right Fan Minimum Voltage
";
CM_ SG_ 404 PDM_fanRightVoltMax "Right Fan Maximum Voltage
";
CM_ SG_ 404 PDM_fanRightVoltAvg "Right Fan Average Voltage
";
CM_ SG_ 404 PDM_counterMsg404 "Counter Message 404
";
CM_ SG_ 403 PDM_fanRightCurrentMin "Right Fan Minimum Current
";
CM_ SG_ 403 PDM_fanRightCurrentMax "Right Fan Maximum Current
";
CM_ SG_ 403 PDM_fanRightCurrentAvg "Right Fan Average Current
";
CM_ SG_ 403 PDM_counterMsg403 "Counter Message 403
";
CM_ SG_ 402 PDM_pdmVoltMin "PDM Minimum Voltage
";
CM_ SG_ 402 PDM_pdmVoltMax "PDM Maximum Voltage
";
CM_ SG_ 402 PDM_pdmVoltAvg "PDM Average Voltage
";
CM_ SG_ 402 PDM_counterMsg402 "Counter Message 302
";
CM_ SG_ 401 PDM_pdmCurrentMin "PDM Minimum Current
";
CM_ SG_ 401 PDM_pdmCurrentMax "PDM Maximum Current
";
CM_ SG_ 401 PDM_pdmCurrentAvg "PDM Average Current
";
CM_ SG_ 401 PDM_counterMsg401 "Counter Message 401
";
CM_ SG_ 400 PDM_vehicleState "fix";
CM_ SG_ 400 PDM_counterMsg400 "Counter Message 400
";
CM_ SG_ 400 PDM_coolingOverrideActive "Cooling Override State
";
CM_ SG_ 400 PDM_brakelightVoltAvg "Brakelight Average Voltage
";
CM_ SG_ 400 PDM_boardTemp "Board Temperature
";
CM_ SG_ 215 BMS_rollingCounter215 "Increments once every 100ms (max value is 255 and rolls over). Can be used to ensure data is updating
";
CM_ SG_ 215 BMS_relayState "Look at utility manual
";
CM_ SG_ 215 BMS_failsafeStatus "Look at utility manual
";
CM_ SG_ 215 BMS_dtcStatus2 "This parameter contains the status of several BMS fault codes. Look at utility manual
";
CM_ SG_ 214 BMS_totalPackCycles "This is the total number of cycles that the battery pack has been put through since the BMS has started keeping track.
";
CM_ SG_ 214 BMS_rollingCounter214 "Increments once every 100ms (max value is 255 and rolls over). Can be used to ensure data is updating
";
CM_ SG_ 214 BMS_populatedCells "This represents the total number of populated (active) cells in the BMS. This can be equal or lower than the Max Cell Number
";
CM_ SG_ 214 BMS_maxCellNumber "The maximum number of cells that the BMS is capable of supporting
";
CM_ SG_ 214 BMS_dtcStatus1 "This parameter contains the status of several BMS fault codes. Look at utility manual
";
CM_ SG_ 213 BMS_rollingCounter213 "Increments once every 100ms (max value is 255 and rolls over). Can be used to ensure data is updating
";
CM_ SG_ 213 BMS_currLimStatus "This value is provided so the reasons for why a current limit either Charge Current Limit or Discharge Current Limit are being reduced by the BMS from the maximum allowable current. Look at utility manual
";
CM_ SG_ 213 BMS_adaptiveTotalCapacity "This is the total number of amphours that the BMS has observed or learned during operation. Over time this will gradually be adjusted as the BMS continues to observe the battery pack
";
CM_ SG_ 213 BMS_adaptiveAmphours "This is the Pack Amphours value equivalent based on the Adaptive Total Capacity metric. This is NOT the total capacity of the battery pack
";
CM_ SG_ 212 BMS_rollingCounter212 "Increments once every 100ms (max value is 255 and rolls over). Can be used to ensure data is updating
";
CM_ SG_ 212 BMS_requestedFanSpeed "This is the current requested speed (0-6) of the battery fan
";
CM_ SG_ 212 BMS_fanVolt "This is the raw voltage measured by the fan monitor circuit. This can be a maximum of 15V
";
CM_ SG_ 212 BMS_fanSpeed "This is the current speed (0-6) of the battery fan. The higher the speed, the faster the fan output should be
";
CM_ SG_ 212 BMS_adaptiveSOC "This is the calculated State of Charge value based on the Adaptive Total Capacity. It is expected for this value to differ, at least slightly, from the overall pack State of Charge parameter as that value is based on the programmed expected capacity
";
CM_ SG_ 211 BMS_rollingCounter211 "Increments once every 100ms (max value is 255 and rolls over). Can be used to ensure data is updating
";
CM_ SG_ 211 BMS_maxPackDCL "This value is the programmed maximum continuous pack Discharge Current Limit
";
CM_ SG_ 211 BMS_maxPackCCL "This value is the programmed maximum continuous pack Charge Current Limit
";
CM_ SG_ 211 BMS_avgPackCurr "This is the AVERAGE current pack amperage value for the battery pack. This will report a constant 0 if no current sensor is selected. The average is taken over the last 1 second of operation so it will lag the instantaneous pack current value
";
CM_ SG_ 210 BMS_rollingCounter210 "Increments once every 100ms (max value is 255 and rolls over). Can be used to ensure data is updating
";
CM_ SG_ 210 BMS_packOpenVolt "This is the current total pack Open Voltage value
";
CM_ SG_ 210 BMS_packDischargeCurrLimkW "This is the pack Discharge Current Limit expressed in kilowatts as opposed to amps
";
CM_ SG_ 210 BMS_packDischargeCurrLim "This is the pack Discharge Current Limit. This value is, by default, reported as a positive value from 0 to whatever the maximum discharge current limit is set to
";
CM_ SG_ 209 BMS_totalPackADC "This is the raw voltage value from the total pack voltage sensor (NOT the sum of all the cell voltages). Only available on BMS models that support the separate total pack sensor
";
CM_ SG_ 209 BMS_rollingCounter209 "Increments once every 100ms (max value is 255 and rolls over). Can be used to ensure data is updating
";
CM_ SG_ 209 BMS_packChargeCurrLimkW "This is the pack Charge Current Limit expressed in kilowatts as opposed to amps
";
CM_ SG_ 209 BMS_packChargeCurrLim "This is the pack Charge Current Limit. The value is, by default, reported as a positive value from 0 to whatever the maximum charge current limit is set to
";
CM_ SG_ 208 BMS_rollingCounter208 "Increments once every 100ms (max value is 255 and rolls over). Can be used to ensure data is updating
";
CM_ SG_ 208 BMS_lowCellVoltID "This value is the ID of the lowest cell voltage measured by the BMS. The value is 1 based (valid range: 1-180)
";
CM_ SG_ 208 BMS_lowCellResistanceID "This value is the ID of the lowest cell resistance measured by the BMS. The value is 1 based (valid range: 1-180)
";
CM_ SG_ 208 BMS_lowCellOpenVoltID "This value is the ID of the lowest cell open (sitting) voltage measured by the BMS. The value is 1 based (valid range: 1-180)
";
CM_ SG_ 208 BMS_highCellVoltID "This value is the ID of the highest cell voltage measured by the BMS. The value is 1 based (valid range: 1-180)
";
CM_ SG_ 208 BMS_highCellResistanceID "This value is the ID of the highest cell resistance measured by the BMS. The value is 1 based (valid range: 1-180)
";
CM_ SG_ 208 BMS_highCellOpenVoltID "This value is the ID of the highest cell open (sitting) voltage measured by the BMS. The value is 1 based (valid range: 1-180)
";
CM_ SG_ 207 BMS_rollingCounter207 "Increments once every 100ms (max value is 255 and rolls over). Can be used to ensure data is updating
";
CM_ SG_ 207 BMS_pwrInputVolt "This is the voltage of the power source that directly powers the BMS (12v-24v nominal for the standard Orion BMS). NOTE: This value will read lower than the actual input voltage seen at the BMS due to internal diode voltage drop
";
CM_ SG_ 207 BMS_minCellVolt "This value is the minimum cell voltage that the BMS is using to limit how low individual cell voltages are allowed to be pulled down to
";
CM_ SG_ 207 BMS_maxCellVolt "This value is the maximum cell voltage that the BMS is using to limit how high individual cell voltages can be. This can be useful for communicating with chargers or charging stations expecting a maximum cell voltage that they are able to charge up to
";
CM_ SG_ 206 BMS_rollingCounter206 "Increments once every 100ms (max value is 255 and rolls over). Can be used to ensure data is updating
";
CM_ SG_ 206 BMS_lowCellInternalResistance "This is the Internal Resistance of the lowest measured cell in the battery pack
";
CM_ SG_ 206 BMS_highCellInternalResistance "This is the Internal Resistance of the highest measured cell in the battery pack
";
CM_ SG_ 206 BMS_avgCellInternalResistance "This is the Internal Resistance of the average measured cell in the battery pack
";
CM_ SG_ 205 BMS_rollingCounter205 "Increments once every 100ms (max value is 255 and rolls over). Can be used to ensure data is updating
";
CM_ SG_ 205 BMS_lowCellOpenVolt "This is the Open Voltage of the lowest measured cell in the battery pack
";
CM_ SG_ 205 BMS_highCellOpenVolt "This is the Open Voltage of the highest measured cell in the battery pack
";
CM_ SG_ 205 BMS_avgCellOpenVolt "This is the Open Voltage of the average measured cell in the battery pack
";
CM_ SG_ 204 BMS_rollingCounter204 "Increments once every 100ms (max value is 255 and rolls over). Can be used to ensure data is updating
";
CM_ SG_ 204 BMS_lowCellVolt "This is the voltage of the lowest measured cell in the battery pack
";
CM_ SG_ 204 BMS_highCellVolt "This is the voltage of the highest measured cell in the battery pack
";
CM_ SG_ 204 BMS_avgCellVolt "This is the voltage of the average measured cell in the battery pack
";
CM_ SG_ 203 BMS_rollingCounter203 "Increments once every 100ms (max value is 255 and rolls over). Can be used to ensure data is updating
";
CM_ SG_ 203 BMS_lowestThermistorID "This is the ID of the lowest temperature thermistor being sensed by the BMS. The lowest possible value is 1
";
CM_ SG_ 203 BMS_lowestTemp "This signed value is the lowest temperature measured in the battery pack
";
CM_ SG_ 203 BMS_internalTemp "This signed value is the internal temperature measured by the BMS (specifically, it is the temperature of the heatsink case)
";
CM_ SG_ 203 BMS_highestThermistorID "This is the ID of the highest temperature thermistor being sensed by the BMS. The lowest possible value is 1
";
CM_ SG_ 203 BMS_highestTemp "This signed value is the highest temperature measured in the battery pack
";
CM_ SG_ 203 BMS_avgTemp "This signed value is the average temperature measured in the battery back by the thermistors
";
CM_ SG_ 202 BMS_rollingCounter202 "Increments once every 100ms (max value is 255 and rolls over). Can be used to ensure data is updating
";
CM_ SG_ 202 BMS_packSOH "This is the total state of health for the battery pack
";
CM_ SG_ 202 BMS_packResistance "This is the combined measured internal resistance for the entire battery pack
";
CM_ SG_ 202 BMS_packDOD "This value represents the total pack depth of discharge (that is, the total percent of the battery that has been discharged to this point). This value does not account for any Drift
";
CM_ SG_ 202 BMS_packAmphours "This is the calculated number of amphours remaining in the battery pack. This is used in part to calculate State of Charge
";
CM_ SG_ 201 BMS_rollingCounter201 "Increments once every 100ms (max value is 255 and rolls over). Can be used to ensure data is updating
";
CM_ SG_ 201 BMS_packSummedVolt "This value is the sum of all the cells being monitored by the BMS and represents the overall pack voltage. It is essentially identical to the Pack Voltage value, except that it is reported wit ha higher resolution (0.01V versus 0.1V)
";
CM_ SG_ 201 BMS_minPackVolt "This value is the mainimum pack voltage that the BMS is using to limit how low the pack voltage is allowed to be pulled down to
";
CM_ SG_ 201 BMS_maxPackVolt "This value is the maximum pack voltage that the BMS is using to limit how high the pack voltage can be. This can be useful for communicating with chargers or charging stations expecting a maximum pack voltage value they are able to charge up to
";
CM_ SG_ 200 BMS_rollingCounter200 "Increments once every 100ms (max value is 255 and rolls over). Can be used to ensure data is updating
";
CM_ SG_ 200 BMS_packVolt "This is the instantaneous total pack voltage value
";
CM_ SG_ 200 BMS_packSOC "This is the pack State of Charge
";
CM_ SG_ 200 BMS_packCurr "This is the current pack amperage value for the battery pack. This will report a constant 0 if no current sensor is selected
";
CM_ SG_ 161 VCU_wheelLockupRR "RR wheel lockup, 0 = no, 1 = yes
";
CM_ SG_ 161 VCU_wheelLockupRL "RL wheel lockup, 0 = no, 1 = yes
";
CM_ SG_ 161 VCU_wheelLockupFR "FR wheel lockup, 0 = no, 1 = yes
";
CM_ SG_ 161 VCU_wheelLockupFL "FL wheel lockup, 0 = no, 1 = yes
";
CM_ SG_ 161 VCU_counterMsg161 "Counter Message 115
";
CM_ SG_ 160 VCU_tcTorqueReduction "TC Torque Reduction
";
CM_ SG_ 160 VCU_tcSlipAimValue "TC Slip Aim Value
";
CM_ SG_ 160 VCU_tcSlipAimError "TC Slip Aim Error
";
CM_ SG_ 160 VCU_counterMsg160 "Counter Message 114
";
CM_ SG_ 159 VCU_counterMsg159 "Counter Message 113
";
CM_ SG_ 159 VCU_brakePressureR "Rear Brake Pressure
";
CM_ SG_ 159 VCU_brakePressureF "Front Brake Pressure
";
CM_ SG_ 159 VCU_brakeBias "BP_F / (BP_F + BP_R)
";
CM_ SG_ 158 VCU_suspensionTravelFR "FR Suspension Travel
";
CM_ SG_ 158 VCU_suspensionTravelFL "FL Suspension Travel
";
CM_ SG_ 158 VCU_counterMsg158 "Counter Message 110
";
CM_ SG_ 164 VCU_flowRateMotorIn "Motor In Flow Rate
";
CM_ SG_ 164 VCU_flowRateInverterOut "Inverter Out Flow Rate
";
CM_ SG_ 164 VCU_flowRateInverterIn "Inverter In Flow Rate
";
CM_ SG_ 164 VCU_counterMsg162 "Counter Message 109
";
CM_ SG_ 157 VCU_tireTempRRO "RRO Tire Temperature
";
CM_ SG_ 157 VCU_tireTempRRM "RRM Tire Temperature
";
CM_ SG_ 157 VCU_tireTempRRI "RRI Tire Temperature
";
CM_ SG_ 157 VCU_counterMsg157 "Counter Message 108
";
CM_ SG_ 156 VCU_tireTempRLO "RLO Tire Temperature
";
CM_ SG_ 156 VCU_tireTempRLM "RLM Tire Temperature
";
CM_ SG_ 156 VCU_tireTempRLI "RLI Tire Temperature
";
CM_ SG_ 156 VCU_counterMsg156 "Counter Message 107
";
CM_ SG_ 155 VCU_rotorTempRR "RR Rotor Temperature
";
CM_ SG_ 155 VCU_rotorTempRL "RL Rotor Temperature
";
CM_ SG_ 155 VCU_counterMsg155 "Counter Message 105
";
CM_ SG_ 154 VCU_suspensionTravelRR "RR Suspension Travel
";
CM_ SG_ 154 VCU_suspensionTravelRL "RL Suspension Travel
";
CM_ SG_ 154 VCU_counterMsg154 "Counter Message 104
";
CM_ SG_ 153 VCU_tireTempFRO "FRO Tire Temperature
";
CM_ SG_ 153 VCU_tireTempFRM "FRM Tire Temperature
";
CM_ SG_ 153 VCU_tireTempFRI "FRI Tire Temperature
";
CM_ SG_ 153 VCU_counterMsg153 "Counter Message 103
";
CM_ SG_ 152 VCU_tireTempFLO "FLO Tire Temperature
";
CM_ SG_ 152 VCU_tireTempFLM "FLM Tire Temperature
";
CM_ SG_ 152 VCU_tireTempFLI "FLI Tire Temperature
";
CM_ SG_ 152 VCU_counterMsg152 "Counter Message 102
";
CM_ SG_ 151 VCU_rotorTempFR "FR Rotor Temperature
";
CM_ SG_ 151 VCU_rotorTempFL "FL Rotor Temperature
";
CM_ SG_ 151 VCU_counterMsg151 "Counter Message 101
";
CM_ SG_ 150 VCU_throttlePosition "Throttle Position
";
CM_ SG_ 150 VCU_tcSet "TC Setting
";
CM_ SG_ 150 VCU_counterMsg150 "Counter Message 100
";
CM_ SG_ 150 VCU_brakePosition "Brake Position
";
BA_DEF_  "BusType" STRING ;
BA_DEF_DEF_  "BusType" "CAN";
